AUTOSAR XML (schema 4-2-2)
package /SwComponentType
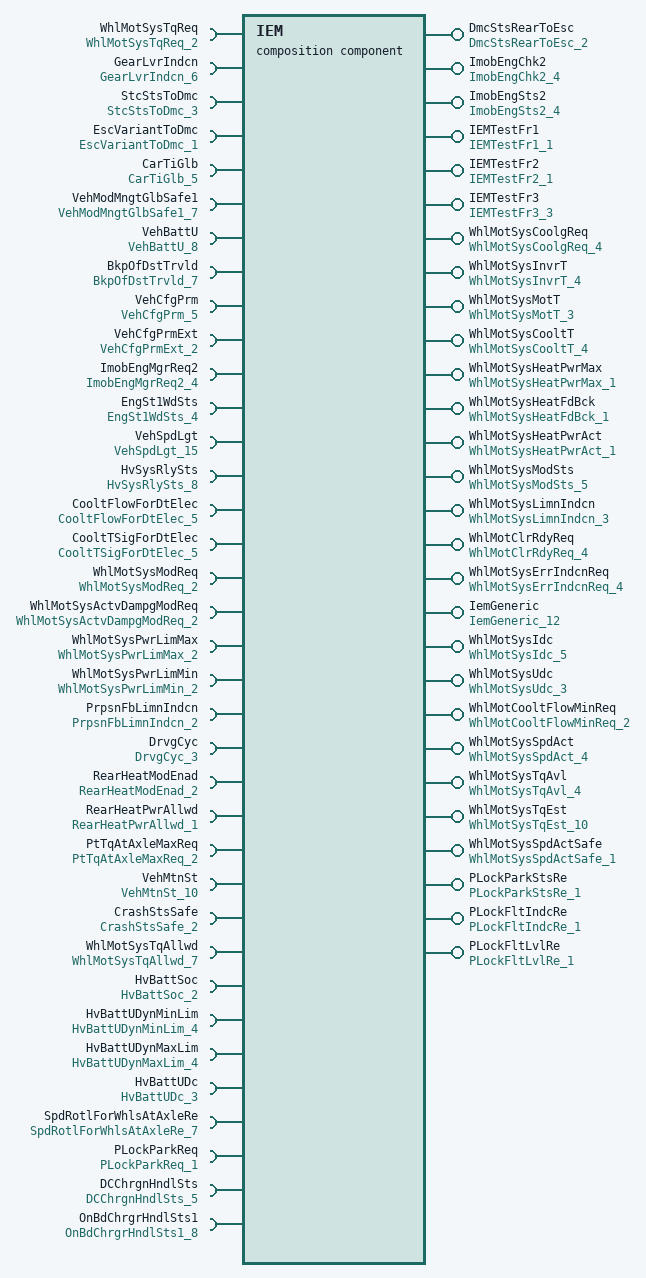
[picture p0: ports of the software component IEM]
  composition sw component type IEM
    28 x provide port:
      DmcStsRearToEsc: nonqueued-sender-com-spec{composite-network-representations=[{leaf-element=DmcStsRearToEsc.DmcSts, network-representation={base-type=DMC_1, compu {0=DMC_Init, 1=DMC_On, 2=DMC_Off, 3=DMC_Fault; unit Unitless}, "DmcSts"}}, {leaf-element=DmcStsRearToEsc.DmcActAppTarTq, network-representation={base-type=Tq35_1, compu {phys=raw for raw -30000..30000; unit NewtonMeter}, "DMCActAppTarTq"}}, {leaf-element=DmcStsRearToEsc.Cntr, network-representation={base-type=UInt4_2, compu {identical; unit Unitless}, "Cntr"}}, {leaf-element=DmcStsRearToEsc.Chks, network-representation={base-type=UInt8_2, compu {identical; unit Unitless}, "Chks"}}, {leaf-element=DmcStsRearToEsc.DmcSWInfo, network-representation={base-type=UInt16_2, compu {identical; unit Unitless}, "DmCSWinformation"}}], data-element=DmcStsRearToEsc, uses-end-to-end-protection=true, init-value=constant-reference=DmcStsRearToEsc_2}, provided-interface=DmcStsRearToEsc_2
      ImobEngChk2: nonqueued-sender-com-spec{composite-network-representations=[{leaf-element=ImobEngChk2.ImobEngChkSts, network-representation={base-type=AvlSts2_2, compu {0=AvlSts2_NotAvl, 1=AvlSts2_Avl; unit Unitless}, "Message from IEM to CEM that challenge is available and 7 bytes of challenge. Message to CEM Challenge available"}}, {leaf-element=ImobEngChk2.ImobEngDataChk0, network-representation={base-type=UInt8_2, compu {identical; unit Unitless}, "Message from IEM to CEM that challenge is available and 7 bytes of challenge. Byte 0"}}, {leaf-element=ImobEngChk2.ImobEngDataChk1, network-representation={base-type=UInt8_2, compu {identical; unit Unitless}, "Message from IEM to CEM that challenge is available and 7 bytes of challenge. Byte 1"}}, {leaf-element=ImobEngChk2.ImobEngDataChk2, network-representation={base-type=UInt8_2, compu {identical; unit Unitless}, "Message from IEM to CEM that challenge is available and 7 bytes of challenge. Byte 2"}}, {leaf-element=ImobEngChk2.ImobEngDataChk3, network-representation={base-type=UInt8_2, compu {identical; unit Unitless}, "Message from IEM to CEM that challenge is available and 7 bytes of challenge. Byte 3"}}, {leaf-element=ImobEngChk2.ImobEngDataChk4, network-representation={base-type=UInt8_2, compu {identical; unit Unitless}, "Message from IEM to CEM that challenge is available and 7 bytes of challenge. Byte 4"}}, {leaf-element=ImobEngChk2.ImobEngDataChk5, network-representation={base-type=UInt8_2, compu {identical; unit Unitless}, "Message from IEM to CEM that challenge is available and 7 bytes of challenge. Byte 5"}}, {leaf-element=ImobEngChk2.ImobEngDataChk6, network-representation={base-type=UInt8_2, compu {identical; unit Unitless}, "Message from IEM to CEM that challenge is available and 7 bytes of challenge. Byte 6"}}], data-element=ImobEngChk2, init-value=constant-reference=ImobEngChk2_4}, provided-interface=ImobEngChk2_4
      ImobEngSts2: nonqueued-sender-com-spec{data-element=ImobEngSts2, network-representation={base-type=ImobSts_2, compu-method=ImobSts_1, "IEM CEM message immo status. Can be undefined, immobilised, motive mobilised or non motive mobilised."}, init-value=constant-reference=ImobEngSts2_4}, provided-interface=ImobEngSts2_4
      IEMTestFr1: nonqueued-sender-com-spec{composite-network-representations=[{leaf-element=IEMTestFr1.Byte0, network-representation={base-type=UInt8_2, compu {identical; unit Unitless}, "DTC1 status"}}, {leaf-element=IEMTestFr1.Byte1, network-representation={base-type=UInt8_2, compu {identical; unit Unitless}, "DTC1 low byte"}}, {leaf-element=IEMTestFr1.Byte2, network-representation={base-type=UInt8_2, compu {identical; unit Unitless}, "DTC1 middle byte"}}, {leaf-element=IEMTestFr1.Byte3, network-representation={base-type=UInt8_2, compu {identical; unit Unitless}, "DTC1 high byte"}}, {leaf-element=IEMTestFr1.Byte4, network-representation={base-type=UInt8_2, compu {identical; unit Unitless}, "DTC2 status"}}, {leaf-element=IEMTestFr1.Byte5, network-representation={base-type=UInt8_2, compu {identical; unit Unitless}, "DTC2 low byte"}}, {leaf-element=IEMTestFr1.Byte6, network-representation={base-type=UInt8_2, compu {identical; unit Unitless}, "DTC2 middle byte"}}, {leaf-element=IEMTestFr1.Byte7, network-representation={base-type=UInt8_2, compu {identical; unit Unitless}, "DTC2 high byte"}}], data-element=IEMTestFr1, init-value=constant-reference=IEMTestFr1_1}, provided-interface=IEMTestFr1_1
      IEMTestFr2: nonqueued-sender-com-spec{composite-network-representations=[{leaf-element=IEMTestFr2.Byte0, network-representation={base-type=UInt8_2, compu {identical; unit Unitless}, "DTC1 status"}}, {leaf-element=IEMTestFr2.Byte1, network-representation={base-type=UInt8_2, compu {identical; unit Unitless}, "DTC1 low byte"}}, {leaf-element=IEMTestFr2.Byte2, network-representation={base-type=UInt8_2, compu {identical; unit Unitless}, "DTC1 middle byte"}}, {leaf-element=IEMTestFr2.Byte3, network-representation={base-type=UInt8_2, compu {identical; unit Unitless}, "DTC1 high byte"}}, {leaf-element=IEMTestFr2.Byte4, network-representation={base-type=UInt8_2, compu {identical; unit Unitless}, "DTC2 status"}}, {leaf-element=IEMTestFr2.Byte5, network-representation={base-type=UInt8_2, compu {identical; unit Unitless}, "DTC2 low byte"}}, {leaf-element=IEMTestFr2.Byte6, network-representation={base-type=UInt8_2, compu {identical; unit Unitless}, "DTC2 middle byte"}}, {leaf-element=IEMTestFr2.Byte7, network-representation={base-type=UInt8_2, compu {identical; unit Unitless}, "DTC2 high byte"}}], data-element=IEMTestFr2, init-value=constant-reference=IEMTestFr2_1}, provided-interface=IEMTestFr2_1
      IEMTestFr3: nonqueued-sender-com-spec{composite-network-representations=[{leaf-element=IEMTestFr3.Byte0, network-representation={base-type=UInt8_2, compu {identical; unit Unitless}, "Info0"}}, {leaf-element=IEMTestFr3.Byte1, network-representation={base-type=UInt8_2, compu {identical; unit Unitless}, "Info1"}}, {leaf-element=IEMTestFr3.Byte2, network-representation={base-type=UInt8_2, compu {identical; unit Unitless}, "Info2"}}, {leaf-element=IEMTestFr3.Byte3, network-representation={base-type=UInt8_2, compu {identical; unit Unitless}, "Info3"}}, {leaf-element=IEMTestFr3.Byte4, network-representation={base-type=UInt8_2, compu {identical; unit Unitless}, "Info4"}}, {leaf-element=IEMTestFr3.Byte5, network-representation={base-type=UInt8_2, compu {identical; unit Unitless}, "Info5"}}, {leaf-element=IEMTestFr3.Byte6, network-representation={base-type=UInt8_2, compu {identical; unit Unitless}, "Info6"}}, {leaf-element=IEMTestFr3.Byte7, network-representation={base-type=UInt8_2, compu {identical; unit Unitless}, "Info7"}}], data-element=IEMTestFr3, init-value=constant-reference=IEMTestFr3_3}, provided-interface=IEMTestFr3_3
      WhlMotSysCoolgReq: nonqueued-sender-com-spec{data-element=WhlMotSysCoolgReq, network-representation={base-type=HvCoolg1_2, compu-method=HvCoolg1_1, "Signal to request increased cooling to Erad and IEM.Request is in 3 steps of increased cooling."}, init-value=constant-reference=WhlMotSysCoolgReq_4}, provided-interface=WhlMotSysCoolgReq_4
      WhlMotSysInvrT: nonqueued-sender-com-spec{data-element=WhlMotSysInvrT, network-representation={base-type=T3_2, compu {phys=raw-50 for raw 0..250; unit degC}, "The inverter temperature measured in the IEM."}, init-value=constant-reference=WhlMotSysInvrT_4}, provided-interface=WhlMotSysInvrT_4
      WhlMotSysMotT: nonqueued-sender-com-spec{data-element=WhlMotSysMotT, network-representation={base-type=T3_2, compu {phys=raw-50 for raw 0..250; unit degC}, "The temperature of motor"}, init-value=constant-reference=WhlMotSysMotT_3}, provided-interface=WhlMotSysMotT_3
      WhlMotSysCooltT: nonqueued-sender-com-spec{data-element=WhlMotSysCooltT, network-representation={base-type=HvT1_3, compu {phys=raw-40 for raw 0..255; unit degC}, "Measured coolant temperature in rear axle inverter in degC"}, init-value=constant-reference=WhlMotSysCooltT_4}, provided-interface=WhlMotSysCooltT_4
      WhlMotSysHeatPwrMax: nonqueued-sender-com-spec{data-element=WhlMotSysHeatPwrMax, network-representation={base-type=IsgHeatPwr_1, compu {phys=raw*50 for raw 0..255; unit W}, "The electrical power required by the current maximum heating power of the rear motor"}, init-value=constant-reference=WhlMotSysHeatPwrMax_1}, provided-interface=WhlMotSysHeatPwrMax_1
      WhlMotSysHeatFdBck: nonqueued-sender-com-spec{data-element=WhlMotSysHeatFdBck, network-representation={base-type=WhlMotSysHeatFdBck_1, compu-method=WhlMotSysHeatFdBck_1, "The feedback of the rear motor to responds to the heating enabling signal of ECM"}, init-value=constant-reference=WhlMotSysHeatFdBck_1}, provided-interface=WhlMotSysHeatFdBck_1
      WhlMotSysHeatPwrAct: nonqueued-sender-com-spec{data-element=WhlMotSysHeatPwrAct, network-representation={base-type=IsgHeatPwr_1, compu {phys=raw*50 for raw 0..255; unit W}, "The actual electrical energy consumption for active heating of rear motor"}, init-value=constant-reference=WhlMotSysHeatPwrAct_1}, provided-interface=WhlMotSysHeatPwrAct_1
      WhlMotSysModSts: nonqueued-sender-com-spec{data-element=WhlMotSysModSts, network-representation={base-type=WhlMotSysModStsTyp2_2, compu-method=WhlMotSysModStsTyp2_2, "Reflects the current operating mode of the IEM."}, init-value=constant-reference=WhlMotSysModSts_5}, provided-interface=WhlMotSysModSts_5
      WhlMotSysLimnIndcn: nonqueued-sender-com-spec{data-element=WhlMotSysLimnIndcn, network-representation={base-type=UInt16_2, compu {identical; unit Unitless}, "The limitation indication of derating conditions"}, init-value=constant-reference=WhlMotSysLimnIndcn_3}, provided-interface=WhlMotSysLimnIndcn_3
      WhlMotClrRdyReq: nonqueued-sender-com-spec{data-element=WhlMotClrRdyReq, network-representation={base-type=OnOff1_2, compu {0=OnOff1_Off, 1=OnOff1_On; unit Unitless}, "WhlMotClrRdyReq"}, init-value=constant-reference=WhlMotClrRdyReq_4}, provided-interface=WhlMotClrRdyReq_4
      WhlMotSysErrIndcnReq: nonqueued-sender-com-spec{data-element=WhlMotSysErrIndcnReq, network-representation={base-type=OnOff1_2, compu {0=OnOff1_Off, 1=OnOff1_On; unit Unitless}, "WhlMotSysErrIndcnReq"}, init-value=constant-reference=WhlMotSysErrIndcnReq_4}, provided-interface=WhlMotSysErrIndcnReq_4
      IemGeneric: nonqueued-sender-com-spec{composite-network-representations=[{leaf-element=IemGeneric.EMQnty, network-representation={base-type=UInt4_2, compu {identical; unit Unitless}, "Quantity of electric motor"}}, {leaf-element=IemGeneric.EMSeqNr, network-representation={base-type=UInt4_2, compu {identical; unit Unitless}, "Sequence number of electric motor"}}, {leaf-element=IemGeneric.DTCSts, network-representation={base-type=UInt8_2, compu {identical; unit Unitless}, "DTC Status"}}, {leaf-element=IemGeneric.DTCLow, network-representation={base-type=UInt8_2, compu {identical; unit Unitless}, "DTC low byte for non OBD"}}, {leaf-element=IemGeneric.DTCMid, network-representation={base-type=UInt8_2, compu {identical; unit Unitless}, "DTC middle byte for non OBD DTC low byte for OBD"}}, {leaf-element=IemGeneric.DTCHig, network-representation={base-type=UInt8_2, compu {identical; unit Unitless}, "DTC high byte for non OBD or OBD"}}, {leaf-element=IemGeneric.TypeInfo, network-representation={base-type=UInt4_2, compu {identical; unit Unitless}, "Indicate different EDS suppliers. OEM defines this value. 0=not defined 1=PMA1 VseA, with ratio=10.134 2=PMA1 Nidec,with ratio=10.294 3=PMA1 VREMT,with ratio=11.56 4=SPAL Scheaffler,with ratio=9.071 5=SPA Simens, with ratio=10.008 6=PMA2 VREMT,with ratio=11.209 7=EPA ZF,with radio=9.187 8=EPA Polestar,with 2-gear ratio=7.155 and 13.645 9=PMA2 UAES,with ratio=11.067"}}, {leaf-element=IemGeneric.MotTAlrmSt, network-representation={base-type=AlrmSt_2, compu {0=AlrmSt_Disarmd, 1=AlrmSt_Armd, 2=AlrmSt_Actv; unit Unitless}, "Motor temperature alarm status"}}, {leaf-element=IemGeneric.InvrtTAlrmSt, network-representation={base-type=AlrmSt_2, compu {0=AlrmSt_Disarmd, 1=AlrmSt_Armd, 2=AlrmSt_Actv; unit Unitless}, "Inverter temperature alarm status"}}, {leaf-element=IemGeneric.FltAlrmSt, network-representation={base-type=AlrmSt_2, compu {0=AlrmSt_Disarmd, 1=AlrmSt_Armd, 2=AlrmSt_Actv; unit Unitless}, "Fault alarm status"}}, {leaf-element=IemGeneric.SpdAlrmSt, network-representation={base-type=AlrmSt_2, compu {0=AlrmSt_Disarmd, 1=AlrmSt_Armd, 2=AlrmSt_Actv; unit Unitless}, "Over speed alarm status"}}, {leaf-element=IemGeneric.IacAlrmSt, network-representation={base-type=AlrmSt_2, compu {0=AlrmSt_Disarmd, 1=AlrmSt_Armd, 2=AlrmSt_Actv; unit Unitless}, "3 Phase current alarm status"}}, {leaf-element=IemGeneric.UDcAlrmSt, network-representation={base-type=AlrmSt_2, compu {0=AlrmSt_Disarmd, 1=AlrmSt_Armd, 2=AlrmSt_Actv; unit Unitless}, "High voltage alarm status"}}, {leaf-element=IemGeneric.RslAlrmSt, network-representation={base-type=AlrmSt_2, compu {0=AlrmSt_Disarmd, 1=AlrmSt_Armd, 2=AlrmSt_Actv; unit Unitless}, "Resolver fault alarm status"}}, {leaf-element=IemGeneric.ADAlrmSt, network-representation={base-type=AlrmSt_2, compu {0=AlrmSt_Disarmd, 1=AlrmSt_Armd, 2=AlrmSt_Actv; unit Unitless}, "Active Discharge fault alarm status"}}, {leaf-element=IemGeneric.ModStatusRms, network-representation={base-type=ModStatusRms_2, compu-method=ModStatusRms_2, "Motor status for RMS monitor"}}], data-element=IemGeneric, init-value=constant-reference=IemGeneric_12}, provided-interface=IemGeneric_12
      WhlMotSysIdc: nonqueued-sender-com-spec{data-element=WhlMotSysIdc, network-representation={base-type=Ampr1_1, compu {phys=raw*0.1-818.8 for raw 0..16380; unit A}, "DC current measured in the IEM."}, init-value=constant-reference=WhlMotSysIdc_5}, provided-interface=WhlMotSysIdc_5
      WhlMotSysUdc: nonqueued-sender-com-spec{data-element=WhlMotSysUdc, network-representation={base-type=HvU1_2, compu {phys=raw*0.25 for raw 0..2044; unit Volt}, "The DC voltage of rear motor"}, init-value=constant-reference=WhlMotSysUdc_3}, provided-interface=WhlMotSysUdc_3
      WhlMotCooltFlowMinReq: nonqueued-sender-com-spec{data-element=WhlMotCooltFlowMinReq, network-representation={base-type=CooltFlowForDtElec1_2, compu {phys=raw*0.01 for raw 0..1023; unit L / min}, "Minimum coolant flow required by rear wheel motor"}, init-value=constant-reference=WhlMotCooltFlowMinReq_2}, provided-interface=WhlMotCooltFlowMinReq_2
      WhlMotSysSpdAct: nonqueued-sender-com-spec{data-element=WhlMotSysSpdAct, network-representation={base-type=IsgSpdWSgnTyp_2, compu {phys=raw for raw -16384..16383; unit rpm}, "The actual rotational speed of rear motor"}, init-value=constant-reference=WhlMotSysSpdAct_4}, provided-interface=WhlMotSysSpdAct_4
      WhlMotSysTqAvl: nonqueued-sender-com-spec{composite-network-representations=[{leaf-element=WhlMotSysTqAvl.TqAvlMax, network-representation={base-type=HvTq1_2, compu {phys=raw*4-8188 for raw 0..4095; unit NewtonMeter}, "Max available torque"}}, {leaf-element=WhlMotSysTqAvl.TqAvlMin, network-representation={base-type=HvTq1_2, compu {phys=raw*4-8188 for raw 0..4095; unit NewtonMeter}, "Min available torque"}}], data-element=WhlMotSysTqAvl, init-value=constant-reference=WhlMotSysTqAvl_4}, provided-interface=WhlMotSysTqAvl_4
      WhlMotSysTqEst: nonqueued-sender-com-spec{composite-network-representations=[{leaf-element=WhlMotSysTqEst.Cntr, network-representation={base-type=UInt4_2, compu {identical; unit Unitless}, "Counter of estimation torque"}}, {leaf-element=WhlMotSysTqEst.Chks, network-representation={base-type=UInt8_2, compu {identical; unit Unitless}, "Checksum of estimation torque"}}, {leaf-element=WhlMotSysTqEst.QualityFactor, network-representation={base-type=QualityFactor_2, compu-method=QualityFactor_1, "Quality factor of estimation torque"}}, {leaf-element=WhlMotSysTqEst.IsgTqAct, network-representation={base-type=Tq34_1, compu {phys=raw-8188 for raw 0..16380; unit NewtonMeter}, "Estimation torque of Rear Axle Control"}}], data-element=WhlMotSysTqEst, uses-end-to-end-protection=true, init-value=constant-reference=WhlMotSysTqEst_10}, provided-interface=WhlMotSysTqEst_10
      WhlMotSysSpdActSafe: nonqueued-sender-com-spec{composite-network-representations=[{leaf-element=WhlMotSysSpdActSafe.IsgSpdWSgnTyp, network-representation={base-type=IsgSpdWSgnTyp_2, compu {phys=raw for raw -16384..16383; unit rpm}, "Safe EM motor shaft speed."}}, {leaf-element=WhlMotSysSpdActSafe.Chks, network-representation={base-type=UInt8_2, compu {identical; unit Unitless}, "checksum"}}, {leaf-element=WhlMotSysSpdActSafe.Cntr, network-representation={base-type=UInt4_2, compu {identical; unit Unitless}, "counter"}}, {leaf-element=WhlMotSysSpdActSafe.Qf, network-representation={base-type=GenQf1_2, compu-method=GenQf1_1, "quality factor"}}], data-element=WhlMotSysSpdActSafe, uses-end-to-end-protection=true, init-value=constant-reference=WhlMotSysSpdActSafe_1}, provided-interface=WhlMotSysSpdActSafe_1
      PLockParkStsRe: nonqueued-sender-com-spec{data-element=PLockParkStsRe, network-representation={base-type=ParkSts_1, compu-method=ParkSts_1, "P-lock status (IEM)"}, init-value=constant-reference=PLockParkStsRe_1}, provided-interface=PLockParkStsRe_1
      PLockFltIndcRe: nonqueued-sender-com-spec{data-element=PLockFltIndcRe, network-representation={base-type=FltIndcn_1, compu-method=FltIndcn_1, "Fault indication signal for P-lock, for rear electric drive"}, init-value=constant-reference=PLockFltIndcRe_1}, provided-interface=PLockFltIndcRe_1
      PLockFltLvlRe: nonqueued-sender-com-spec{data-element=PLockFltLvlRe, network-representation={base-type=FltLvl_1, compu {0=FltLvl_NoFlt, 1=FltLvl_FltLvl1, 2=FltLvl_FltLvl2; unit Unitless}, "P-lock fault level, for rear electric drive."}, init-value=constant-reference=PLockFltLvlRe_1}, provided-interface=PLockFltLvlRe_1
    36 x require port:
      WhlMotSysTqReq: nonqueued-receiver-com-spec{data-element=WhlMotSysTqReq, network-representation={base-type=HvTq1_2, compu {phys=raw*4-8188 for raw 0..4095; unit NewtonMeter}, "Requested electric motor torque referred to the wheel axle. The torque is positive in the forward rotation direction."}, alive-timeout=0.5, init-value=constant-reference=WhlMotSysTqReq_2}, required-interface=WhlMotSysTqReq_2
      GearLvrIndcn: nonqueued-receiver-com-spec{data-element=GearLvrIndcn, network-representation={base-type=GearLvrIndcn2_2, compu-method=GearLvrIndcn2_1, "Gear lever indication (drivetrain position) to the driver. If drivetrain position is not possible to decide signal is set to undefined. Valid for automatic vehicles."}, init-value=constant-reference=GearLvrIndcn_6}, required-interface=GearLvrIndcn_6
      StcStsToDmc: nonqueued-receiver-com-spec{composite-network-representations=[{leaf-element=StcStsToDmc.StcStsToDmcFrnt, network-representation={base-type=ModeDMC_1, compu {0=ModeDMC_Off, 1=ModeDMC_Rpm, 2=ModeDMC_Trq; unit Unitless}, "StcSts to Dmc frint"}}, {leaf-element=StcStsToDmc.StcStsToDmcRear, network-representation={base-type=ModeDMC_1, compu {0=ModeDMC_Off, 1=ModeDMC_Rpm, 2=ModeDMC_Trq; unit Unitless}, "StcSts to DMC Rear"}}, {leaf-element=StcStsToDmc.EngRotTarSpdDMCFrnt, network-representation={base-type=UInt16_2, compu {identical; unit Unitless}, "EngRoTarSpdDMC frint"}}, {leaf-element=StcStsToDmc.EngRotTarSpdDMCRear, network-representation={base-type=UInt16_2, compu {identical; unit Unitless}, "EngRoTarSpdDMC rear"}}, {leaf-element=StcStsToDmc.Chks, network-representation={base-type=UInt8_2, compu {identical; unit Unitless}, "Chks"}}, {leaf-element=StcStsToDmc.Cntr, network-representation={base-type=UInt4_2, compu {identical; unit Unitless}, "Cntr"}}], data-element=StcStsToDmc, uses-end-to-end-protection=true, init-value=constant-reference=StcStsToDmc_3}, required-interface=StcStsToDmc_3
      EscVariantToDmc: nonqueued-receiver-com-spec{composite-network-representations=[{leaf-element=EscVariantToDmc.EscVariantToDmc, network-representation={base-type=UInt8_2, compu {identical; unit Unitless}, "Esc Variant"}}, {leaf-element=EscVariantToDmc.Chks, network-representation={base-type=UInt8_2, compu {identical; unit Unitless}, "Chks"}}, {leaf-element=EscVariantToDmc.Cntr, network-representation={base-type=UInt4_2, compu {identical; unit Unitless}, "Cntr"}}], data-element=EscVariantToDmc, uses-end-to-end-protection=true, init-value=constant-reference=EscVariantToDmc_1}, required-interface=EscVariantToDmc_1
      CarTiGlb: nonqueued-receiver-com-spec{data-element=CarTiGlb, network-representation={base-type=CarTiGlb_2, compu {phys=raw*0.1 for raw 0..4294967295; unit s}, "Presents a tiime value that shall be used by all ECUs to time-stamp diagnsotic trouble codes (DTC) according to the requirements for Global DTC snapshot data."}, init-value=constant-reference=CarTiGlb_5}, required-interface=CarTiGlb_5
      VehModMngtGlbSafe1: nonqueued-receiver-com-spec{composite-network-representations=[{leaf-element=VehModMngtGlbSafe1.UsgModSts, network-representation={base-type=UsgModSts1_2, compu-method=UsgModSts1_1, "UsageMode Status"}}, {leaf-element=VehModMngtGlbSafe1.CarModSts1, network-representation={base-type=CarModSts1_2, compu-method=CarModSts1_1, "CarMode Status"}}, {leaf-element=VehModMngtGlbSafe1.CarModSubtypWdCarModSubtyp, network-representation={base-type=Nr5_2, compu {identical; unit Unitless}, "CarMode substate status"}}, {leaf-element=VehModMngtGlbSafe1.EgyLvlElecMai, network-representation={base-type=UInt4_2, compu {identical; unit Unitless}, "Main energy level in the vehicle."}}, {leaf-element=VehModMngtGlbSafe1.EgyLvlElecSubtyp, network-representation={base-type=UInt4_2, compu {identical; unit Unitless}, "Substate of the energy level in the vehicle."}}, {leaf-element=VehModMngtGlbSafe1.PwrLvlElecMai, network-representation={base-type=UInt4_2, compu {identical; unit Unitless}, "Main Power level in the vehicle."}}, {leaf-element=VehModMngtGlbSafe1.PwrLvlElecSubtyp, network-representation={base-type=UInt4_2, compu {identical; unit Unitless}, "Substate of the power level in the vehicle."}}, {leaf-element=VehModMngtGlbSafe1.FltEgyCnsWdSts, network-representation={base-type=FltEgyCns1_2, compu {0=FltEgyCns1_NoFlt, 1=FltEgyCns1_Flt; unit Unitless}, "High quiescent current detected by CEM via BMS."}}, {leaf-element=VehModMngtGlbSafe1.Chks, network-representation={base-type=UInt8_2, compu {identical; unit Unitless}, "Checksum"}}, {leaf-element=VehModMngtGlbSafe1.Cntr, network-representation={base-type=UInt4_2, compu {identical; unit Unitless}, "Counter"}}], data-element=VehModMngtGlbSafe1, init-value=constant-reference=VehModMngtGlbSafe1_7}, required-interface=VehModMngtGlbSafe1_7
      VehBattU: nonqueued-receiver-com-spec{composite-network-representations=[{leaf-element=VehBattU.SysU, network-representation={base-type=U1_2, compu {phys=raw*0.1 for raw 0..250; unit Volt}, "Vehicle System Voltage At 12V side"}}, {leaf-element=VehBattU.SysUQf, network-representation={base-type=GenQf1_2, compu-method=GenQf1_1, "Present vehicle voltage measured by CEM with QF"}}], data-element=VehBattU, init-value=constant-reference=VehBattU_8}, required-interface=VehBattU_8
      BkpOfDstTrvld: nonqueued-receiver-com-spec{data-element=BkpOfDstTrvld, network-representation={base-type=Len31_2, compu {phys=raw for raw 0..2000000; unit km}, "total traveled distance."}, init-value=constant-reference=BkpOfDstTrvld_7}, required-interface=BkpOfDstTrvld_7
      VehCfgPrm: nonqueued-receiver-com-spec{composite-network-representations=[{leaf-element=VehCfgPrm.BlkIDBytePosn1, network-representation={base-type=Nr2_3, compu {phys=raw for raw 0..255; unit Unitless}, "signal block counter."}}, {leaf-element=VehCfgPrm.CCPBytePosn2, network-representation={base-type=Nr2_3, compu {phys=raw for raw 0..255; unit Unitless}, "(BlockID-1)*7 + 1."}}, {leaf-element=VehCfgPrm.CCPBytePosn3, network-representation={base-type=Nr2_3, compu {phys=raw for raw 0..255; unit Unitless}, "(BlockID-1)*7 + 2."}}, {leaf-element=VehCfgPrm.CCPBytePosn4, network-representation={base-type=Nr2_3, compu {phys=raw for raw 0..255; unit Unitless}, "(BlockID-1)*7 + 3."}}, {leaf-element=VehCfgPrm.CCPBytePosn5, network-representation={base-type=Nr2_3, compu {phys=raw for raw 0..255; unit Unitless}, "(BlockID-1)*7 + 4."}}, {leaf-element=VehCfgPrm.CCPBytePosn6, network-representation={base-type=Nr2_3, compu {phys=raw for raw 0..255; unit Unitless}, "(BlockID-1)*7 + 5."}}, {leaf-element=VehCfgPrm.CCPBytePosn7, network-representation={base-type=Nr2_3, compu {phys=raw for raw 0..255; unit Unitless}, "(BlockID-1)*7 + 6."}}, {leaf-element=VehCfgPrm.CCPBytePosn8, network-representation={base-type=Nr2_3, compu {phys=raw for raw 0..255; unit Unitless}, "(BlockID-1)*7 + 7."}}], data-element=VehCfgPrm, init-value=constant-reference=VehCfgPrm_5}, required-interface=VehCfgPrm_5
      VehCfgPrmExt: nonqueued-receiver-com-spec{composite-network-representations=[{leaf-element=VehCfgPrmExt.BlkIDBytePosn1, network-representation={base-type=Nr2_3, compu {phys=raw for raw 0..255; unit Unitless}, "CarConfigExtended BlockID"}}, {leaf-element=VehCfgPrmExt.CCPBytePosn2, network-representation={base-type=Nr2_3, compu {phys=raw for raw 0..255; unit Unitless}, "CarConfigExtended BytePos2"}}, {leaf-element=VehCfgPrmExt.CCPBytePosn3, network-representation={base-type=Nr2_3, compu {phys=raw for raw 0..255; unit Unitless}, "CarConfigExtended BytePos3"}}, {leaf-element=VehCfgPrmExt.CCPBytePosn4, network-representation={base-type=Nr2_3, compu {phys=raw for raw 0..255; unit Unitless}, "CarConfigExtended BytePos4"}}, {leaf-element=VehCfgPrmExt.CCPBytePosn5, network-representation={base-type=Nr2_3, compu {phys=raw for raw 0..255; unit Unitless}, "CarConfigExtended BytePos5"}}, {leaf-element=VehCfgPrmExt.CCPBytePosn6, network-representation={base-type=Nr2_3, compu {phys=raw for raw 0..255; unit Unitless}, "CarConfigExtended BytePos6"}}, {leaf-element=VehCfgPrmExt.CCPBytePosn7, network-representation={base-type=Nr2_3, compu {phys=raw for raw 0..255; unit Unitless}, "CarConfigExtended BytePos7"}}, {leaf-element=VehCfgPrmExt.CCPBytePosn8, network-representation={base-type=Nr2_3, compu {phys=raw for raw 0..255; unit Unitless}, "CarConfigExtended BytePos8"}}], data-element=VehCfgPrmExt, init-value=constant-reference=VehCfgPrmExt_2}, required-interface=VehCfgPrmExt_2
      ImobEngMgrReq2: nonqueued-receiver-com-spec{composite-network-representations=[{leaf-element=ImobEngMgrReq2.ImobEngMgrCmdTar1, network-representation={base-type=ImobEngMgrReqCmd_2, compu-method=ImobEngMgrReqCmd_1, "Command from CEM to IEM with desired immo status and 7 bytes of response Command from CEM"}}, {leaf-element=ImobEngMgrReq2.ImobEngDataMgrReq0, network-representation={base-type=UInt8_2, compu {identical; unit Unitless}, "Command from CEM to IEM with desired immo status and 7 bytes of response Byte 0"}}, {leaf-element=ImobEngMgrReq2.ImobEngDataMgrReq1, network-representation={base-type=UInt8_2, compu {identical; unit Unitless}, "Command from CEM to IEM with desired immo status and 7 bytes of response Byte 1"}}, {leaf-element=ImobEngMgrReq2.ImobEngDataMgrReq2, network-representation={base-type=UInt8_2, compu {identical; unit Unitless}, "Command from CEM to IEM with desired immo status and 7 bytes of response Byte 2"}}, {leaf-element=ImobEngMgrReq2.ImobEngDataMgrReq3, network-representation={base-type=UInt8_2, compu {identical; unit Unitless}, "Command from CEM to IEM with desired immo status and 7 bytes of response Byte 3"}}, {leaf-element=ImobEngMgrReq2.ImobEngDataMgrReq4, network-representation={base-type=UInt8_2, compu {identical; unit Unitless}, "Command from CEM to IEM with desired immo status and 7 bytes of response Byte 4"}}, {leaf-element=ImobEngMgrReq2.ImobEngDataMgrReq5, network-representation={base-type=UInt8_2, compu {identical; unit Unitless}, "Command from CEM to IEM with desired immo status and 7 bytes of response Byte 5"}}, {leaf-element=ImobEngMgrReq2.ImobEngDataMgrReq6, network-representation={base-type=UInt8_2, compu {identical; unit Unitless}, "Command from CEM to IEM with desired immo status and 7 bytes of response Byte 6"}}], data-element=ImobEngMgrReq2, init-value=constant-reference=ImobEngMgrReq2_4}, required-interface=ImobEngMgrReq2_4
      EngSt1WdSts: nonqueued-receiver-com-spec{composite-network-representations=[{leaf-element=EngSt1WdSts.EngSt1WdSts, network-representation={base-type=EngSt1_2, compu-method=EngSt1_1, "Signaling the state of the powerpack"}}, {leaf-element=EngSt1WdSts.Chks, network-representation={base-type=UInt8_2, compu {identical; unit Unitless}, "checksum"}}, {leaf-element=EngSt1WdSts.Cntr, network-representation={base-type=UInt4_2, compu {identical; unit Unitless}, "counter"}}], data-element=EngSt1WdSts, init-value=constant-reference=EngSt1WdSts_4}, required-interface=EngSt1WdSts_4
      VehSpdLgt: nonqueued-receiver-com-spec{composite-network-representations=[{leaf-element=VehSpdLgt.VehSpdLgtA, network-representation={base-type=Spd1_2, compu {phys=raw*0.00391 for raw 0..31970; unit m/s}, "Vehicle speed longitudinal based on wheel speed sensors and longitudinal acceleration."}}, {leaf-element=VehSpdLgt.VehSpdLgtQf, network-representation={base-type=GenQf1_2, compu-method=GenQf1_1, "Quality factor for vehicle speed as measured by wheel speed sensors and longitudinal acceleration."}}, {leaf-element=VehSpdLgt.VehSpdLgtCntr, network-representation={base-type=UInt4_2, compu {identical; unit Unitless}, "Counter"}}, {leaf-element=VehSpdLgt.VehSpdLgtChks, network-representation={base-type=UInt8_2, compu {identical; unit Unitless}, "Checksum"}}], data-element=VehSpdLgt, uses-end-to-end-protection=true, init-value=constant-reference=VehSpdLgt_15}, required-interface=VehSpdLgt_15
      HvSysRlySts: nonqueued-receiver-com-spec{composite-network-representations=[{leaf-element=HvSysRlySts.HvSysRlySts, network-representation={base-type=HvActvnSts_2, compu-method=HvActvnSts_1, "Actual state of the main contactors."}}, {leaf-element=HvSysRlySts.Cntr, network-representation={base-type=UInt4_2, compu {identical; unit Unitless}, "Counter for E2E"}}, {leaf-element=HvSysRlySts.Chks, network-representation={base-type=UInt8_2, compu {identical; unit Unitless}, "Checksum for E2E"}}], data-element=HvSysRlySts, uses-end-to-end-protection=true, alive-timeout=0.35, init-value=constant-reference=HvSysRlySts_8}, required-interface=HvSysRlySts_8
      CooltFlowForDtElec: nonqueued-receiver-com-spec{data-element=CooltFlowForDtElec, network-representation={base-type=CooltFlow2_2, compu {phys=raw*0.1 for raw 0..511; unit L / min}, "Predicted coolant low for Electric Drivetrain (ED) coolant circuit."}, init-value=constant-reference=CooltFlowForDtElec_5}, required-interface=CooltFlowForDtElec_5
      CooltTSigForDtElec: nonqueued-receiver-com-spec{data-element=CooltTSigForDtElec, network-representation={base-type=CooltTHiResl_2, compu {phys=raw*0.1-40 for raw 0..1800; unit degC}, "Coolant temperature measured by sensors installed in emotor cooling citcuit."}, init-value=constant-reference=CooltTSigForDtElec_5}, required-interface=CooltTSigForDtElec_5
      WhlMotSysModReq: nonqueued-receiver-com-spec{data-element=WhlMotSysModReq, network-representation={base-type=WhlMotSysModStsTyp1_2, compu-method=WhlMotSysModStsTyp1_1, "Mode request for motor drive system connected to wheel shaft."}, alive-timeout=0.5, init-value=constant-reference=WhlMotSysModReq_2}, required-interface=WhlMotSysModReq_2
      WhlMotSysActvDampgModReq: nonqueued-receiver-com-spec{data-element=WhlMotSysActvDampgModReq, network-representation={base-type=WhlMotSysActvDampgModCodSts_2, compu-method=WhlMotSysActvDampgModCodSts_1, "ERAD active damping mod request."}, init-value=constant-reference=WhlMotSysActvDampgModReq_2}, required-interface=WhlMotSysActvDampgModReq_2
      WhlMotSysPwrLimMax: nonqueued-receiver-com-spec{data-element=WhlMotSysPwrLimMax, network-representation={base-type=PrpsnPwrLimMax_2, compu {phys=raw*0.5 for raw 0..1022; unit kW}, "Maximum electric motor powerlimit on DC side. Positive power means power flowing into inverter."}, init-value=constant-reference=WhlMotSysPwrLimMax_2}, required-interface=WhlMotSysPwrLimMax_2
      WhlMotSysPwrLimMin: nonqueued-receiver-com-spec{data-element=WhlMotSysPwrLimMin, network-representation={base-type=PrpsnPwrLimMin_2, compu {phys=raw*0.5-511 for raw 0..1022; unit kW}, "Minimum electric motor powerlimit on DC side. Positive power means power flowing into inverter."}, init-value=constant-reference=WhlMotSysPwrLimMin_2}, required-interface=WhlMotSysPwrLimMin_2
      PrpsnFbLimnIndcn: nonqueued-receiver-com-spec{data-element=PrpsnFbLimnIndcn, network-representation={base-type=UInt4_2, compu {identical; unit Unitless}, "Feedback signal that the present limitation has lead to a recofiguraton that has affected the driver."}, init-value=constant-reference=PrpsnFbLimnIndcn_2}, required-interface=PrpsnFbLimnIndcn_2
      DrvgCyc: nonqueued-receiver-com-spec{data-element=DrvgCyc, network-representation={base-type=OnOff1_2, compu {0=OnOff1_Off, 1=OnOff1_On; unit Unitless}, "Transition from 0 to 1 indicates a start of a new Driving Cycle."}, init-value=constant-reference=DrvgCyc_3}, required-interface=DrvgCyc_3
      RearHeatModEnad: nonqueued-receiver-com-spec{data-element=RearHeatModEnad, network-representation={base-type=FrntHeatModEnad_1, compu-method=FrntHeatModEnad_1, "Active heating enabling signal for rear motor"}, init-value=constant-reference=RearHeatModEnad_2}, required-interface=RearHeatModEnad_2
      RearHeatPwrAllwd: nonqueued-receiver-com-spec{data-element=RearHeatPwrAllwd, network-representation={base-type=IsgHeatPwr_1, compu {phys=raw*50 for raw 0..255; unit W}, "The allowed electrial energy for active heating of the rear motor"}, init-value=constant-reference=RearHeatPwrAllwd_1}, required-interface=RearHeatPwrAllwd_1
      PtTqAtAxleMaxReq: nonqueued-receiver-com-spec{composite-network-representations=[{leaf-element=PtTqAtAxleMaxReq.PtTqAtAxleFrntReq, network-representation={base-type=Tq2_2, compu {phys=raw for raw -20000..20000; unit NewtonMeter}, "Maximum allowed powertrain applied torque on the front axle."}}, {leaf-element=PtTqAtAxleMaxReq.PtTqAtAxleReReq, network-representation={base-type=Tq2_2, compu {phys=raw for raw -20000..20000; unit NewtonMeter}, "Maximum allowed powertrain applied torque on the rear axle."}}, {leaf-element=PtTqAtAxleMaxReq.Chks, network-representation={base-type=UInt8_2, compu {identical; unit Unitless}, "checksum"}}, {leaf-element=PtTqAtAxleMaxReq.Cntr, network-representation={base-type=UInt4_2, compu {identical; unit Unitless}, "counter"}}], data-element=PtTqAtAxleMaxReq, alive-timeout=0.5, init-value=constant-reference=PtTqAtAxleMaxReq_2}, required-interface=PtTqAtAxleMaxReq_2
      VehMtnSt: nonqueued-receiver-com-spec{composite-network-representations=[{leaf-element=VehMtnSt.VehMtnSt, network-representation={base-type=VehMtnSt2_2, compu-method=VehMtnSt2_1, "Vehicle motion state information based on wheel speed sensors. Provides information about vehicle stand still and vehicle rolling direction. Vehicle motion state"}}, {leaf-element=VehMtnSt.VehMtnStChks, network-representation={base-type=UInt8_2, compu {identical; unit Unitless}, "Vehicle motion state information based on wheel speed sensors. Provides information about vehicle stand still and vehicle rolling direction. Checksum for vehicle motion state"}}, {leaf-element=VehMtnSt.VehMtnStCntr, network-representation={base-type=UInt4_2, compu {identical; unit Unitless}, "Vehicle motion state information based on wheel speed sensors. Provides information about vehicle stand still and vehicle rolling direction. Counter for vehicle motion state"}}], data-element=VehMtnSt, uses-end-to-end-protection=true, init-value=constant-reference=VehMtnSt_10}, required-interface=VehMtnSt_10
      CrashStsSafe: nonqueued-receiver-com-spec{composite-network-representations=[{leaf-element=CrashStsSafe.Sts, network-representation={base-type=CrashSts2_2, compu {0=CrashSts2_NoCrash, 1=CrashSts2_Crash; unit Unitless}, "Information if a crash has been detected by SRS."}}, {leaf-element=CrashStsSafe.Chks, network-representation={base-type=UInt8_2, compu {identical; unit Unitless}, "Checksum for E2E"}}, {leaf-element=CrashStsSafe.Cntr, network-representation={base-type=UInt4_2, compu {identical; unit Unitless}, "Counter for E2E"}}], data-element=CrashStsSafe, uses-end-to-end-protection=true, alive-timeout=1.0, init-value=constant-reference=CrashStsSafe_2}, required-interface=CrashStsSafe_2
      WhlMotSysTqAllwd: nonqueued-receiver-com-spec{composite-network-representations=[{leaf-element=WhlMotSysTqAllwd.WhlMotSysTqAllwd, network-representation={base-type=UInt2_2, compu {identical; unit Unitless}, "Indication if ERAD is allowed to apply propulsive or regenerative torque on wheels. Bit 0: Propulsive torque allowed Bit 1: Regenerative torque allowed"}}, {leaf-element=WhlMotSysTqAllwd.Chks, network-representation={base-type=UInt8_2, compu {identical; unit Unitless}, "Checksum for WhlMotSysTqAllwd"}}, {leaf-element=WhlMotSysTqAllwd.Cntr, network-representation={base-type=UInt4_2, compu {identical; unit Unitless}, "Counter for WhlMotSysTqAllwd"}}], data-element=WhlMotSysTqAllwd, uses-end-to-end-protection=true, alive-timeout=0.5, init-value=constant-reference=WhlMotSysTqAllwd_7}, required-interface=WhlMotSysTqAllwd_7
      HvBattSoc: nonqueued-receiver-com-spec{data-element=HvBattSoc, network-representation={base-type=Perc7_2, compu {phys=raw*0.05 for raw 0..2000; unit %}, "Actual state of charge of the Hv Battery."}, init-value=constant-reference=HvBattSoc_2}, required-interface=HvBattSoc_2
      HvBattUDynMinLim: nonqueued-receiver-com-spec{data-element=HvBattUDynMinLim, network-representation={base-type=HvU1_2, compu {phys=raw*0.25 for raw 0..2044; unit Volt}, "The pack voltage low limit of the Hv Battery, dynamically based on cell voltage distribution. At pack voltages below this limit, there is risk for contactor openeing due to too low cell voltage"}, init-value=constant-reference=HvBattUDynMinLim_4}, required-interface=HvBattUDynMinLim_4
      HvBattUDynMaxLim: nonqueued-receiver-com-spec{data-element=HvBattUDynMaxLim, network-representation={base-type=HvU1_2, compu {phys=raw*0.25 for raw 0..2044; unit Volt}, "The pack voltage high limit of the Hv Battery, dynamically based on cell voltage distribution. At pack voltages above this limit, there is risk for contactor openeing due to too high cell voltage."}, init-value=constant-reference=HvBattUDynMaxLim_4}, required-interface=HvBattUDynMaxLim_4
      HvBattUDc: nonqueued-receiver-com-spec{data-element=HvBattUDc, network-representation={base-type=HvU1_2, compu {phys=raw*0.25 for raw 0..2044; unit Volt}, "Actual Hv Battery pack voltage (measuered before contactors, i.e. always giving pack voltage)."}, init-value=constant-reference=HvBattUDc_3}, required-interface=HvBattUDc_3
      SpdRotlForWhlsAtAxleRe: nonqueued-receiver-com-spec{data-element=SpdRotlForWhlsAtAxleRe, network-representation={base-type=N1_2, compu {phys=raw*0.5 for raw 0..32767; unit rpm}, "Average angular velocity of rear wheels."}, init-value=constant-reference=SpdRotlForWhlsAtAxleRe_7}, required-interface=SpdRotlForWhlsAtAxleRe_7
      PLockParkReq: nonqueued-receiver-com-spec{data-element=PLockParkReq, network-representation={base-type=PLockParkRequest_1, compu-method=PLockParkRequest_1, "Park request to P-Lock."}, init-value=constant-reference=PLockParkReq_1}, required-interface=PLockParkReq_1
      DCChrgnHndlSts: nonqueued-receiver-com-spec{data-element=DCChrgnHndlSts, network-representation={base-type=OnBdChrgrHndlSts_2, compu-method=OnBdChrgrHndlSts_1, "Fast charging gun connect state"}, init-value=constant-reference=DCChrgnHndlSts_5}, required-interface=DCChrgnHndlSts_5
      OnBdChrgrHndlSts1: nonqueued-receiver-com-spec{data-element=OnBdChrgrHndlSts1, network-representation={base-type=OnBdChrgrHndlSts1_2, compu-method=OnBdChrgrHndlSts1_2, "Status of the Onboard Charger connection to the grid."}, init-value=constant-reference=OnBdChrgrHndlSts1_8}, required-interface=OnBdChrgrHndlSts1_8
    13 x port group, all with category=PARTIAL_NETWORKING:
      PropulsionStart
        outer-ports:
          IEM/ImobEngChk2
          IEM/ImobEngSts2
          IEM/WhlMotSysInvrT
          IEM/WhlMotSysMotT
          IEM/WhlMotSysCooltT
          IEM/WhlMotSysHeatPwrMax
          IEM/WhlMotSysHeatPwrAct
          IEM/WhlMotSysModSts
          IEM/WhlMotSysLimnIndcn
          IEM/WhlMotClrRdyReq
          IEM/WhlMotSysErrIndcnReq
          IEM/IemGeneric
          IEM/WhlMotSysIdc
          IEM/WhlMotSysUdc
          IEM/WhlMotSysSpdAct
          IEM/WhlMotSysTqAvl
          IEM/WhlMotSysTqEst
          IEM/PLockParkStsRe
          IEM/PLockFltIndcRe
          IEM/PLockFltLvlRe
          IEM/ImobEngMgrReq2
          IEM/EngSt1WdSts
          IEM/WhlMotSysModReq
          IEM/WhlMotSysActvDampgModReq
          IEM/WhlMotSysPwrLimMax
          IEM/WhlMotSysPwrLimMin
          IEM/PrpsnFbLimnIndcn
          IEM/DrvgCyc
          IEM/DCChrgnHndlSts
          IEM/OnBdChrgrHndlSts1
          IEM/HvSysRlySts
          IEM/EngSt1WdSts
          IEM/PrpsnFbLimnIndcn
          IEM/WhlMotSysActvDampgModReq
          IEM/WhlMotSysModReq
          IEM/WhlMotSysPwrLimMax
          IEM/WhlMotSysPwrLimMin
          IEM/WhlMotSysTqAllwd
          IEM/GearLvrIndcn
          IEM/HvBattSoc
          IEM/DrvgCyc
          IEM/EngSt1WdSts
          IEM/HvBattUDynMinLim
          IEM/HvBattUDynMaxLim
          IEM/HvBattUDc
          IEM/WhlMotSysTqReq
          IEM/PLockParkReq
      Immobilizer
        outer-ports:
          IEM/ImobEngChk2
          IEM/ImobEngSts2
          IEM/WhlMotSysHeatPwrMax
          IEM/WhlMotSysHeatPwrAct
          IEM/WhlMotSysModSts
          IEM/IemGeneric
          IEM/WhlMotSysIdc
          IEM/WhlMotSysUdc
          IEM/WhlMotSysSpdAct
          IEM/ImobEngMgrReq2
          IEM/EngSt1WdSts
          IEM/WhlMotSysModReq
          IEM/WhlMotSysActvDampgModReq
          IEM/WhlMotSysPwrLimMax
          IEM/WhlMotSysPwrLimMin
          IEM/EngSt1WdSts
          IEM/VehMtnSt
          IEM/WhlMotSysActvDampgModReq
          IEM/WhlMotSysModReq
          IEM/WhlMotSysPwrLimMax
          IEM/WhlMotSysPwrLimMin
          IEM/WhlMotSysTqAllwd
          IEM/GearLvrIndcn
          IEM/VehSpdLgt
          IEM/EngSt1WdSts
          IEM/WhlMotSysTqReq
          IEM/SpdRotlForWhlsAtAxleRe
      Diagnostics
        outer-ports:
          IEM/ImobEngChk2
          IEM/ImobEngSts2
          IEM/WhlMotSysCoolgReq
          IEM/WhlMotSysInvrT
          IEM/WhlMotSysMotT
          IEM/WhlMotSysCooltT
          IEM/WhlMotSysHeatPwrMax
          IEM/WhlMotSysHeatFdBck
          IEM/WhlMotSysHeatPwrAct
          IEM/WhlMotSysModSts
          IEM/WhlMotSysLimnIndcn
          IEM/WhlMotClrRdyReq
          IEM/WhlMotSysErrIndcnReq
          IEM/IemGeneric
          IEM/WhlMotSysIdc
          IEM/WhlMotSysUdc
          IEM/WhlMotCooltFlowMinReq
          IEM/WhlMotSysSpdAct
          IEM/WhlMotSysTqAvl
          IEM/WhlMotSysTqEst
          IEM/WhlMotSysSpdActSafe
          IEM/PLockParkStsRe
          IEM/PLockFltIndcRe
          IEM/PLockFltLvlRe
          IEM/ImobEngMgrReq2
          IEM/EngSt1WdSts
          IEM/VehSpdLgt
          IEM/HvSysRlySts
          IEM/CooltFlowForDtElec
          IEM/CooltTSigForDtElec
          IEM/WhlMotSysModReq
          IEM/WhlMotSysActvDampgModReq
          IEM/WhlMotSysPwrLimMax
          IEM/WhlMotSysPwrLimMin
          IEM/PrpsnFbLimnIndcn
          IEM/DrvgCyc
          IEM/CooltFlowForDtElec
          IEM/CooltTSigForDtElec
          IEM/RearHeatModEnad
          IEM/RearHeatPwrAllwd
          IEM/DCChrgnHndlSts
          IEM/OnBdChrgrHndlSts1
          IEM/PtTqAtAxleMaxReq
          IEM/HvSysRlySts
          IEM/EngSt1WdSts
          IEM/VehMtnSt
          IEM/PrpsnFbLimnIndcn
          IEM/CrashStsSafe
          IEM/WhlMotSysActvDampgModReq
          IEM/WhlMotSysModReq
          IEM/WhlMotSysPwrLimMax
          IEM/WhlMotSysPwrLimMin
          IEM/WhlMotSysTqAllwd
          IEM/GearLvrIndcn
          IEM/HvBattSoc
          IEM/DrvgCyc
          IEM/VehSpdLgt
          IEM/EngSt1WdSts
          IEM/HvBattUDynMinLim
          IEM/HvBattUDynMaxLim
          IEM/HvBattUDc
          IEM/WhlMotSysTqReq
          IEM/SpdRotlForWhlsAtAxleRe
          IEM/PLockParkReq
          IEM/VehSpdLgt
      VehicleModeManagement
        outer-ports:
          IEM/ImobEngChk2
          IEM/ImobEngSts2
          IEM/WhlMotSysCoolgReq
          IEM/WhlMotSysInvrT
          IEM/WhlMotSysMotT
          IEM/WhlMotSysCooltT
          IEM/WhlMotSysHeatPwrMax
          IEM/WhlMotSysHeatFdBck
          IEM/WhlMotSysHeatPwrAct
          IEM/WhlMotSysModSts
          IEM/WhlMotSysLimnIndcn
          IEM/WhlMotClrRdyReq
          IEM/WhlMotSysErrIndcnReq
          IEM/IemGeneric
          IEM/WhlMotSysIdc
          IEM/WhlMotSysUdc
          IEM/WhlMotCooltFlowMinReq
          IEM/WhlMotSysSpdAct
          IEM/WhlMotSysTqAvl
          IEM/WhlMotSysTqEst
          IEM/WhlMotSysSpdActSafe
          IEM/PLockParkStsRe
          IEM/PLockFltIndcRe
          IEM/PLockFltLvlRe
          IEM/ImobEngMgrReq2
          IEM/EngSt1WdSts
          IEM/VehSpdLgt
          IEM/HvSysRlySts
          IEM/CooltFlowForDtElec
          IEM/CooltTSigForDtElec
          IEM/WhlMotSysModReq
          IEM/WhlMotSysActvDampgModReq
          IEM/WhlMotSysPwrLimMax
          IEM/WhlMotSysPwrLimMin
          IEM/PrpsnFbLimnIndcn
          IEM/DrvgCyc
          IEM/CooltFlowForDtElec
          IEM/CooltTSigForDtElec
          IEM/RearHeatModEnad
          IEM/RearHeatPwrAllwd
          IEM/DCChrgnHndlSts
          IEM/OnBdChrgrHndlSts1
          IEM/PtTqAtAxleMaxReq
          IEM/HvSysRlySts
          IEM/EngSt1WdSts
          IEM/VehMtnSt
          IEM/PrpsnFbLimnIndcn
          IEM/CrashStsSafe
          IEM/WhlMotSysActvDampgModReq
          IEM/WhlMotSysModReq
          IEM/WhlMotSysPwrLimMax
          IEM/WhlMotSysPwrLimMin
          IEM/WhlMotSysTqAllwd
          IEM/GearLvrIndcn
          IEM/HvBattSoc
          IEM/DrvgCyc
          IEM/VehSpdLgt
          IEM/EngSt1WdSts
          IEM/HvBattUDynMinLim
          IEM/HvBattUDynMaxLim
          IEM/HvBattUDc
          IEM/WhlMotSysTqReq
          IEM/SpdRotlForWhlsAtAxleRe
          IEM/PLockParkReq
          IEM/VehSpdLgt
      ChargingHV
        outer-ports:
          IEM/WhlMotSysInvrT
          IEM/WhlMotSysMotT
          IEM/WhlMotSysCooltT
          IEM/WhlMotSysHeatPwrMax
          IEM/WhlMotSysHeatPwrAct
          IEM/WhlMotSysModSts
          IEM/WhlMotSysLimnIndcn
          IEM/WhlMotSysErrIndcnReq
          IEM/IemGeneric
          IEM/WhlMotSysIdc
          IEM/WhlMotSysUdc
          IEM/WhlMotSysSpdAct
          IEM/WhlMotSysTqAvl
          IEM/WhlMotSysTqEst
          IEM/WhlMotSysSpdActSafe
          IEM/PLockParkStsRe
          IEM/PLockFltIndcRe
          IEM/PLockFltLvlRe
          IEM/WhlMotSysModReq
          IEM/WhlMotSysActvDampgModReq
          IEM/WhlMotSysPwrLimMax
          IEM/WhlMotSysPwrLimMin
          IEM/PrpsnFbLimnIndcn
          IEM/DrvgCyc
          IEM/DCChrgnHndlSts
          IEM/OnBdChrgrHndlSts1
          IEM/HvSysRlySts
          IEM/EngSt1WdSts
          IEM/PrpsnFbLimnIndcn
          IEM/WhlMotSysActvDampgModReq
          IEM/WhlMotSysModReq
          IEM/WhlMotSysPwrLimMax
          IEM/WhlMotSysPwrLimMin
          IEM/WhlMotSysTqAllwd
          IEM/GearLvrIndcn
          IEM/HvBattSoc
          IEM/DrvgCyc
          IEM/EngSt1WdSts
          IEM/HvBattUDynMinLim
          IEM/HvBattUDynMaxLim
          IEM/HvBattUDc
          IEM/WhlMotSysTqReq
          IEM/PLockParkReq
      ParkingDrivingClimatization
        outer-ports:
          IEM/WhlMotSysCoolgReq
          IEM/WhlMotSysInvrT
          IEM/WhlMotSysMotT
          IEM/WhlMotSysCooltT
          IEM/WhlMotSysHeatPwrMax
          IEM/WhlMotSysHeatFdBck
          IEM/WhlMotSysHeatPwrAct
          IEM/WhlMotSysModSts
          IEM/WhlMotSysLimnIndcn
          IEM/WhlMotClrRdyReq
          IEM/WhlMotSysErrIndcnReq
          IEM/IemGeneric
          IEM/WhlMotSysIdc
          IEM/WhlMotSysUdc
          IEM/WhlMotCooltFlowMinReq
          IEM/WhlMotSysSpdAct
          IEM/WhlMotSysTqAvl
          IEM/WhlMotSysTqEst
          IEM/CooltFlowForDtElec
          IEM/CooltTSigForDtElec
          IEM/WhlMotSysModReq
          IEM/WhlMotSysActvDampgModReq
          IEM/WhlMotSysPwrLimMax
          IEM/WhlMotSysPwrLimMin
          IEM/PrpsnFbLimnIndcn
          IEM/DrvgCyc
          IEM/CooltFlowForDtElec
          IEM/CooltTSigForDtElec
          IEM/RearHeatModEnad
          IEM/RearHeatPwrAllwd
          IEM/DCChrgnHndlSts
          IEM/OnBdChrgrHndlSts1
          IEM/HvSysRlySts
          IEM/EngSt1WdSts
          IEM/VehMtnSt
          IEM/PrpsnFbLimnIndcn
          IEM/CrashStsSafe
          IEM/WhlMotSysActvDampgModReq
          IEM/WhlMotSysModReq
          IEM/WhlMotSysPwrLimMax
          IEM/WhlMotSysPwrLimMin
          IEM/WhlMotSysTqAllwd
          IEM/GearLvrIndcn
          IEM/HvBattSoc
          IEM/DrvgCyc
          IEM/VehSpdLgt
          IEM/EngSt1WdSts
          IEM/HvBattUDynMinLim
          IEM/HvBattUDynMaxLim
          IEM/HvBattUDc
          IEM/WhlMotSysTqReq
          IEM/SpdRotlForWhlsAtAxleRe
      TelematicsConnectivity
        outer-ports:
          IEM/WhlMotSysInvrT
          IEM/WhlMotSysMotT
          IEM/WhlMotSysCooltT
          IEM/WhlMotSysModSts
          IEM/WhlMotSysLimnIndcn
          IEM/IemGeneric
          IEM/WhlMotSysIdc
          IEM/WhlMotSysUdc
          IEM/WhlMotSysSpdAct
          IEM/WhlMotSysTqEst
          IEM/OnBdChrgrHndlSts1
      VehicleDriving
        outer-ports:
          IEM/WhlMotSysCoolgReq
          IEM/WhlMotSysInvrT
          IEM/WhlMotSysMotT
          IEM/WhlMotSysCooltT
          IEM/WhlMotSysHeatPwrMax
          IEM/WhlMotSysHeatFdBck
          IEM/WhlMotSysHeatPwrAct
          IEM/WhlMotSysModSts
          IEM/WhlMotSysLimnIndcn
          IEM/WhlMotClrRdyReq
          IEM/WhlMotSysErrIndcnReq
          IEM/IemGeneric
          IEM/WhlMotSysIdc
          IEM/WhlMotSysUdc
          IEM/WhlMotCooltFlowMinReq
          IEM/WhlMotSysSpdAct
          IEM/WhlMotSysTqAvl
          IEM/WhlMotSysTqEst
          IEM/WhlMotSysSpdActSafe
          IEM/PLockParkStsRe
          IEM/PLockFltIndcRe
          IEM/PLockFltLvlRe
          IEM/CooltFlowForDtElec
          IEM/CooltTSigForDtElec
          IEM/WhlMotSysModReq
          IEM/WhlMotSysActvDampgModReq
          IEM/WhlMotSysPwrLimMax
          IEM/WhlMotSysPwrLimMin
          IEM/PrpsnFbLimnIndcn
          IEM/DrvgCyc
          IEM/CooltFlowForDtElec
          IEM/CooltTSigForDtElec
          IEM/RearHeatModEnad
          IEM/RearHeatPwrAllwd
          IEM/DCChrgnHndlSts
          IEM/OnBdChrgrHndlSts1
          IEM/PtTqAtAxleMaxReq
          IEM/HvSysRlySts
          IEM/EngSt1WdSts
          IEM/VehMtnSt
          IEM/PrpsnFbLimnIndcn
          IEM/CrashStsSafe
          IEM/WhlMotSysActvDampgModReq
          IEM/WhlMotSysModReq
          IEM/WhlMotSysPwrLimMax
          IEM/WhlMotSysPwrLimMin
          IEM/WhlMotSysTqAllwd
          IEM/GearLvrIndcn
          IEM/HvBattSoc
          IEM/DrvgCyc
          IEM/VehSpdLgt
          IEM/EngSt1WdSts
          IEM/HvBattUDynMinLim
          IEM/HvBattUDynMaxLim
          IEM/HvBattUDc
          IEM/WhlMotSysTqReq
          IEM/SpdRotlForWhlsAtAxleRe
          IEM/PLockParkReq
          IEM/VehSpdLgt
      GlobalShortDuration
        outer-ports:
          IEM/WhlMotSysCooltT
          IEM/WhlMotSysModSts
          IEM/WhlMotSysLimnIndcn
          IEM/WhlMotSysUdc
          IEM/WhlMotSysSpdAct
          IEM/WhlMotSysSpdActSafe
          IEM/DCChrgnHndlSts
          IEM/OnBdChrgrHndlSts1
          IEM/HvSysRlySts
          IEM/VehMtnSt
          IEM/CrashStsSafe
          IEM/HvBattSoc
          IEM/VehSpdLgt
          IEM/HvBattUDynMinLim
          IEM/HvBattUDynMaxLim
          IEM/HvBattUDc
          IEM/SpdRotlForWhlsAtAxleRe
      HVEnergyStorage
        outer-ports:
          IEM/WhlMotSysCoolgReq
          IEM/WhlMotSysInvrT
          IEM/WhlMotSysMotT
          IEM/WhlMotSysCooltT
          IEM/WhlMotSysModSts
          IEM/WhlMotSysLimnIndcn
          IEM/WhlMotSysIdc
          IEM/WhlMotSysUdc
          IEM/WhlMotCooltFlowMinReq
          IEM/CooltFlowForDtElec
          IEM/CooltTSigForDtElec
          IEM/PrpsnFbLimnIndcn
          IEM/CooltFlowForDtElec
          IEM/CooltTSigForDtElec
          IEM/DCChrgnHndlSts
          IEM/HvSysRlySts
          IEM/PrpsnFbLimnIndcn
          IEM/HvBattSoc
          IEM/HvBattUDynMinLim
          IEM/HvBattUDynMaxLim
          IEM/HvBattUDc
      Crash
        outer-ports:
          IEM/WhlMotSysCoolgReq
          IEM/WhlMotSysInvrT
          IEM/WhlMotSysMotT
          IEM/WhlMotSysCooltT
          IEM/WhlMotSysModSts
          IEM/WhlMotSysLimnIndcn
          IEM/WhlMotClrRdyReq
          IEM/WhlMotSysErrIndcnReq
          IEM/WhlMotSysIdc
          IEM/WhlMotSysUdc
          IEM/WhlMotCooltFlowMinReq
          IEM/WhlMotSysSpdAct
          IEM/WhlMotSysTqEst
          IEM/WhlMotSysSpdActSafe
          IEM/CooltFlowForDtElec
          IEM/DrvgCyc
          IEM/CooltFlowForDtElec
          IEM/DCChrgnHndlSts
          IEM/PtTqAtAxleMaxReq
          IEM/HvSysRlySts
          IEM/CrashStsSafe
          IEM/HvBattSoc
          IEM/DrvgCyc
          IEM/HvBattUDynMinLim
          IEM/HvBattUDynMaxLim
          IEM/HvBattUDc
      InfotainmentPush: outer-ports=[IEM/WhlMotSysIdc, IEM/WhlMotSysUdc, IEM/WhlMotSysSpdAct, IEM/WhlMotSysTqEst, IEM/WhlMotSysSpdActSafe]
      Brake: outer-ports=[IEM/WhlMotSysIdc, IEM/WhlMotSysUdc, IEM/WhlMotSysSpdAct, IEM/WhlMotSysTqEst, IEM/WhlMotSysSpdActSafe]
    component IEMDTCS: type=IEMDTCS
    component IEMHOST: type=IEMHOST
    delegate IEMDTCS.DmcStsRearToEsc <-> outer port IEM/DmcStsRearToEsc
    delegate IEMHOST.ImobEngChk2 <-> outer port IEM/ImobEngChk2
    delegate IEMHOST.ImobEngSts2 <-> outer port IEM/ImobEngSts2
    delegate IEMHOST.IEMTestFr{1..3} <-> outer port IEM/IEMTestFr{1..3}
    delegate IEMHOST.WhlMotSysCoolgReq <-> outer port IEM/WhlMotSysCoolgReq
    delegate IEMHOST.WhlMotSysInvrT <-> outer port IEM/WhlMotSysInvrT
    delegate IEMHOST.WhlMotSysMotT <-> outer port IEM/WhlMotSysMotT
    delegate IEMHOST.WhlMotSysCooltT <-> outer port IEM/WhlMotSysCooltT
    delegate IEMHOST.WhlMotSysHeatPwrMax <-> outer port IEM/WhlMotSysHeatPwrMax
    delegate IEMHOST.WhlMotSysHeatFdBck <-> outer port IEM/WhlMotSysHeatFdBck
    delegate IEMHOST.WhlMotSysHeatPwrAct <-> outer port IEM/WhlMotSysHeatPwrAct
    delegate IEMHOST.WhlMotSysModSts <-> outer port IEM/WhlMotSysModSts
    delegate IEMHOST.WhlMotSysLimnIndcn <-> outer port IEM/WhlMotSysLimnIndcn
    delegate IEMHOST.WhlMotClrRdyReq <-> outer port IEM/WhlMotClrRdyReq
    delegate IEMHOST.WhlMotSysErrIndcnReq <-> outer port IEM/WhlMotSysErrIndcnReq
    delegate IEMHOST.IemGeneric <-> outer port IEM/IemGeneric
    delegate IEMHOST.WhlMotSysIdc <-> outer port IEM/WhlMotSysIdc
    delegate IEMHOST.WhlMotSysUdc <-> outer port IEM/WhlMotSysUdc
    delegate IEMHOST.WhlMotCooltFlowMinReq <-> outer port IEM/WhlMotCooltFlowMinReq
    delegate IEMHOST.WhlMotSysSpdAct <-> outer port IEM/WhlMotSysSpdAct
    delegate IEMHOST.WhlMotSysTqAvl <-> outer port IEM/WhlMotSysTqAvl
    delegate IEMHOST.WhlMotSysTqEst <-> outer port IEM/WhlMotSysTqEst
    delegate IEMHOST.WhlMotSysSpdActSafe <-> outer port IEM/WhlMotSysSpdActSafe
    delegate IEMHOST.PLockParkStsRe <-> outer port IEM/PLockParkStsRe
    delegate IEMHOST.PLockFltIndcRe <-> outer port IEM/PLockFltIndcRe
    delegate IEMHOST.PLockFltLvlRe <-> outer port IEM/PLockFltLvlRe
    delegate IEMDTCS.WhlMotSysTqReq <-> outer port IEM/WhlMotSysTqReq
    delegate IEMHOST.WhlMotSysTqReq <-> outer port IEM/WhlMotSysTqReq
    delegate IEMDTCS.GearLvrIndcn <-> outer port IEM/GearLvrIndcn
    delegate IEMHOST.GearLvrIndcn <-> outer port IEM/GearLvrIndcn
    delegate IEMDTCS.StcStsToDmc <-> outer port IEM/StcStsToDmc
    delegate IEMDTCS.EscVariantToDmc <-> outer port IEM/EscVariantToDmc
    delegate IEMHOST.CarTiGlb <-> outer port IEM/CarTiGlb
    delegate IEMHOST.VehModMngtGlbSafe1 <-> outer port IEM/VehModMngtGlbSafe1
    delegate IEMHOST.VehBattU <-> outer port IEM/VehBattU
    delegate IEMHOST.BkpOfDstTrvld <-> outer port IEM/BkpOfDstTrvld
    delegate IEMHOST.VehCfgPrm <-> outer port IEM/VehCfgPrm
    delegate IEMHOST.VehCfgPrmExt <-> outer port IEM/VehCfgPrmExt
    delegate IEMHOST.ImobEngMgrReq2 <-> outer port IEM/ImobEngMgrReq2
    delegate IEMHOST.EngSt1WdSts <-> outer port IEM/EngSt1WdSts
    delegate IEMHOST.VehSpdLgt <-> outer port IEM/VehSpdLgt
    delegate IEMHOST.HvSysRlySts <-> outer port IEM/HvSysRlySts
    delegate IEMHOST.CooltFlowForDtElec <-> outer port IEM/CooltFlowForDtElec
    delegate IEMHOST.CooltTSigForDtElec <-> outer port IEM/CooltTSigForDtElec
    delegate IEMHOST.WhlMotSysModReq <-> outer port IEM/WhlMotSysModReq
    delegate IEMHOST.WhlMotSysActvDampgModReq <-> outer port IEM/WhlMotSysActvDampgModReq
    delegate IEMHOST.WhlMotSysPwrLimMax <-> outer port IEM/WhlMotSysPwrLimMax
    delegate IEMHOST.WhlMotSysPwrLimMin <-> outer port IEM/WhlMotSysPwrLimMin
    delegate IEMHOST.PrpsnFbLimnIndcn <-> outer port IEM/PrpsnFbLimnIndcn
    delegate IEMHOST.DrvgCyc <-> outer port IEM/DrvgCyc
    delegate IEMHOST.RearHeatModEnad <-> outer port IEM/RearHeatModEnad
    delegate IEMHOST.RearHeatPwrAllwd <-> outer port IEM/RearHeatPwrAllwd
    delegate IEMHOST.PtTqAtAxleMaxReq <-> outer port IEM/PtTqAtAxleMaxReq
    delegate IEMHOST.VehMtnSt <-> outer port IEM/VehMtnSt
    delegate IEMHOST.CrashStsSafe <-> outer port IEM/CrashStsSafe
    delegate IEMHOST.WhlMotSysTqAllwd <-> outer port IEM/WhlMotSysTqAllwd
    delegate IEMHOST.HvBattSoc <-> outer port IEM/HvBattSoc
    delegate IEMHOST.HvBattUDynMinLim <-> outer port IEM/HvBattUDynMinLim
    delegate IEMHOST.HvBattUDynMaxLim <-> outer port IEM/HvBattUDynMaxLim
    delegate IEMHOST.HvBattUDc <-> outer port IEM/HvBattUDc
    delegate IEMHOST.SpdRotlForWhlsAtAxleRe <-> outer port IEM/SpdRotlForWhlsAtAxleRe
    delegate IEMHOST.PLockParkReq <-> outer port IEM/PLockParkReq
    delegate IEMHOST.DCChrgnHndlSts <-> outer port IEM/DCChrgnHndlSts
    delegate IEMHOST.OnBdChrgrHndlSts1 <-> outer port IEM/OnBdChrgrHndlSts1
    connect IEMHOST.WhlMotSysSpdActSafe -> IEMDTCS.WhlMotSysSpdActSafe
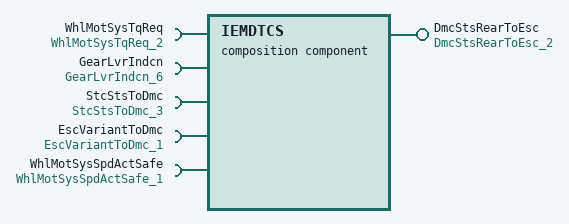
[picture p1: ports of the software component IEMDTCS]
  composition sw component type IEMDTCS
    provide port DmcStsRearToEsc: nonqueued-sender-com-spec{composite-network-representations=[{leaf-element=DmcStsRearToEsc.DmcSts, network-representation={base-type=DMC_1, compu {0=DMC_Init, 1=DMC_On, 2=DMC_Off, 3=DMC_Fault; unit Unitless}, "DmcSts"}}, {leaf-element=DmcStsRearToEsc.DmcActAppTarTq, network-representation={base-type=Tq35_1, compu {phys=raw for raw -30000..30000; unit NewtonMeter}, "DMCActAppTarTq"}}, {leaf-element=DmcStsRearToEsc.Cntr, network-representation={base-type=UInt4_2, compu {identical; unit Unitless}, "Cntr"}}, {leaf-element=DmcStsRearToEsc.Chks, network-representation={base-type=UInt8_2, compu {identical; unit Unitless}, "Chks"}}, {leaf-element=DmcStsRearToEsc.DmcSWInfo, network-representation={base-type=UInt16_2, compu {identical; unit Unitless}, "DmCSWinformation"}}], data-element=DmcStsRearToEsc, uses-end-to-end-protection=true, init-value=constant-reference=DmcStsRearToEsc_2}, provided-interface=DmcStsRearToEsc_2
    5 x require port:
      WhlMotSysTqReq: nonqueued-receiver-com-spec{data-element=WhlMotSysTqReq, network-representation={base-type=HvTq1_2, compu {phys=raw*4-8188 for raw 0..4095; unit NewtonMeter}, "Requested electric motor torque referred to the wheel axle. The torque is positive in the forward rotation direction."}, init-value=constant-reference=WhlMotSysTqReq_2}, required-interface=WhlMotSysTqReq_2
      GearLvrIndcn: nonqueued-receiver-com-spec{data-element=GearLvrIndcn, network-representation={base-type=GearLvrIndcn2_2, compu-method=GearLvrIndcn2_1, "Gear lever indication (drivetrain position) to the driver. If drivetrain position is not possible to decide signal is set to undefined. Valid for automatic vehicles."}, init-value=constant-reference=GearLvrIndcn_6}, required-interface=GearLvrIndcn_6
      StcStsToDmc: nonqueued-receiver-com-spec{composite-network-representations=[{leaf-element=StcStsToDmc.StcStsToDmcFrnt, network-representation={base-type=ModeDMC_1, compu {0=ModeDMC_Off, 1=ModeDMC_Rpm, 2=ModeDMC_Trq; unit Unitless}, "StcSts to Dmc frint"}}, {leaf-element=StcStsToDmc.StcStsToDmcRear, network-representation={base-type=ModeDMC_1, compu {0=ModeDMC_Off, 1=ModeDMC_Rpm, 2=ModeDMC_Trq; unit Unitless}, "StcSts to DMC Rear"}}, {leaf-element=StcStsToDmc.EngRotTarSpdDMCFrnt, network-representation={base-type=UInt16_2, compu {identical; unit Unitless}, "EngRoTarSpdDMC frint"}}, {leaf-element=StcStsToDmc.EngRotTarSpdDMCRear, network-representation={base-type=UInt16_2, compu {identical; unit Unitless}, "EngRoTarSpdDMC rear"}}, {leaf-element=StcStsToDmc.Chks, network-representation={base-type=UInt8_2, compu {identical; unit Unitless}, "Chks"}}, {leaf-element=StcStsToDmc.Cntr, network-representation={base-type=UInt4_2, compu {identical; unit Unitless}, "Cntr"}}], data-element=StcStsToDmc, uses-end-to-end-protection=true, init-value=constant-reference=StcStsToDmc_3}, required-interface=StcStsToDmc_3
      EscVariantToDmc: nonqueued-receiver-com-spec{composite-network-representations=[{leaf-element=EscVariantToDmc.EscVariantToDmc, network-representation={base-type=UInt8_2, compu {identical; unit Unitless}, "Esc Variant"}}, {leaf-element=EscVariantToDmc.Chks, network-representation={base-type=UInt8_2, compu {identical; unit Unitless}, "Chks"}}, {leaf-element=EscVariantToDmc.Cntr, network-representation={base-type=UInt4_2, compu {identical; unit Unitless}, "Cntr"}}], data-element=EscVariantToDmc, uses-end-to-end-protection=true, init-value=constant-reference=EscVariantToDmc_1}, required-interface=EscVariantToDmc_1
      WhlMotSysSpdActSafe: nonqueued-receiver-com-spec{composite-network-representations=[{leaf-element=WhlMotSysSpdActSafe.IsgSpdWSgnTyp, network-representation={base-type=IsgSpdWSgnTyp_2, compu {phys=raw for raw -16384..16383; unit rpm}, "Safe EM motor shaft speed."}}, {leaf-element=WhlMotSysSpdActSafe.Chks, network-representation={base-type=UInt8_2, compu {identical; unit Unitless}, "checksum"}}, {leaf-element=WhlMotSysSpdActSafe.Cntr, network-representation={base-type=UInt4_2, compu {identical; unit Unitless}, "counter"}}, {leaf-element=WhlMotSysSpdActSafe.Qf, network-representation={base-type=GenQf1_2, compu-method=GenQf1_1, "quality factor"}}], data-element=WhlMotSysSpdActSafe, uses-end-to-end-protection=true, init-value=constant-reference=WhlMotSysSpdActSafe_1}, required-interface=WhlMotSysSpdActSafe_1
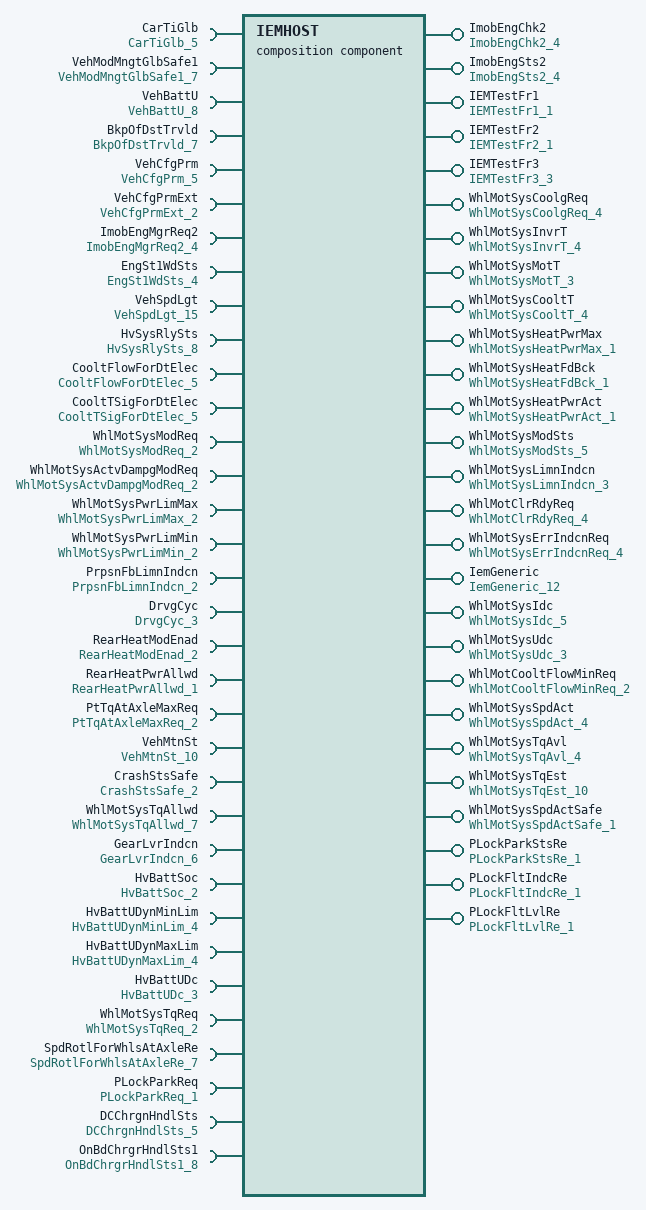
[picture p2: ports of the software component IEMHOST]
  composition sw component type IEMHOST
    27 x provide port:
      ImobEngChk2: nonqueued-sender-com-spec{composite-network-representations=[{leaf-element=ImobEngChk2.ImobEngChkSts, network-representation={base-type=AvlSts2_2, compu {0=AvlSts2_NotAvl, 1=AvlSts2_Avl; unit Unitless}, "Message from IEM to CEM that challenge is available and 7 bytes of challenge. Message to CEM Challenge available"}}, {leaf-element=ImobEngChk2.ImobEngDataChk0, network-representation={base-type=UInt8_2, compu {identical; unit Unitless}, "Message from IEM to CEM that challenge is available and 7 bytes of challenge. Byte 0"}}, {leaf-element=ImobEngChk2.ImobEngDataChk1, network-representation={base-type=UInt8_2, compu {identical; unit Unitless}, "Message from IEM to CEM that challenge is available and 7 bytes of challenge. Byte 1"}}, {leaf-element=ImobEngChk2.ImobEngDataChk2, network-representation={base-type=UInt8_2, compu {identical; unit Unitless}, "Message from IEM to CEM that challenge is available and 7 bytes of challenge. Byte 2"}}, {leaf-element=ImobEngChk2.ImobEngDataChk3, network-representation={base-type=UInt8_2, compu {identical; unit Unitless}, "Message from IEM to CEM that challenge is available and 7 bytes of challenge. Byte 3"}}, {leaf-element=ImobEngChk2.ImobEngDataChk4, network-representation={base-type=UInt8_2, compu {identical; unit Unitless}, "Message from IEM to CEM that challenge is available and 7 bytes of challenge. Byte 4"}}, {leaf-element=ImobEngChk2.ImobEngDataChk5, network-representation={base-type=UInt8_2, compu {identical; unit Unitless}, "Message from IEM to CEM that challenge is available and 7 bytes of challenge. Byte 5"}}, {leaf-element=ImobEngChk2.ImobEngDataChk6, network-representation={base-type=UInt8_2, compu {identical; unit Unitless}, "Message from IEM to CEM that challenge is available and 7 bytes of challenge. Byte 6"}}], data-element=ImobEngChk2, init-value=constant-reference=ImobEngChk2_4}, provided-interface=ImobEngChk2_4
      ImobEngSts2: nonqueued-sender-com-spec{data-element=ImobEngSts2, network-representation={base-type=ImobSts_2, compu-method=ImobSts_1, "IEM CEM message immo status. Can be undefined, immobilised, motive mobilised or non motive mobilised."}, init-value=constant-reference=ImobEngSts2_4}, provided-interface=ImobEngSts2_4
      IEMTestFr1: nonqueued-sender-com-spec{composite-network-representations=[{leaf-element=IEMTestFr1.Byte0, network-representation={base-type=UInt8_2, compu {identical; unit Unitless}, "DTC1 status"}}, {leaf-element=IEMTestFr1.Byte1, network-representation={base-type=UInt8_2, compu {identical; unit Unitless}, "DTC1 low byte"}}, {leaf-element=IEMTestFr1.Byte2, network-representation={base-type=UInt8_2, compu {identical; unit Unitless}, "DTC1 middle byte"}}, {leaf-element=IEMTestFr1.Byte3, network-representation={base-type=UInt8_2, compu {identical; unit Unitless}, "DTC1 high byte"}}, {leaf-element=IEMTestFr1.Byte4, network-representation={base-type=UInt8_2, compu {identical; unit Unitless}, "DTC2 status"}}, {leaf-element=IEMTestFr1.Byte5, network-representation={base-type=UInt8_2, compu {identical; unit Unitless}, "DTC2 low byte"}}, {leaf-element=IEMTestFr1.Byte6, network-representation={base-type=UInt8_2, compu {identical; unit Unitless}, "DTC2 middle byte"}}, {leaf-element=IEMTestFr1.Byte7, network-representation={base-type=UInt8_2, compu {identical; unit Unitless}, "DTC2 high byte"}}], data-element=IEMTestFr1, init-value=constant-reference=IEMTestFr1_1}, provided-interface=IEMTestFr1_1
      IEMTestFr2: nonqueued-sender-com-spec{composite-network-representations=[{leaf-element=IEMTestFr2.Byte0, network-representation={base-type=UInt8_2, compu {identical; unit Unitless}, "DTC1 status"}}, {leaf-element=IEMTestFr2.Byte1, network-representation={base-type=UInt8_2, compu {identical; unit Unitless}, "DTC1 low byte"}}, {leaf-element=IEMTestFr2.Byte2, network-representation={base-type=UInt8_2, compu {identical; unit Unitless}, "DTC1 middle byte"}}, {leaf-element=IEMTestFr2.Byte3, network-representation={base-type=UInt8_2, compu {identical; unit Unitless}, "DTC1 high byte"}}, {leaf-element=IEMTestFr2.Byte4, network-representation={base-type=UInt8_2, compu {identical; unit Unitless}, "DTC2 status"}}, {leaf-element=IEMTestFr2.Byte5, network-representation={base-type=UInt8_2, compu {identical; unit Unitless}, "DTC2 low byte"}}, {leaf-element=IEMTestFr2.Byte6, network-representation={base-type=UInt8_2, compu {identical; unit Unitless}, "DTC2 middle byte"}}, {leaf-element=IEMTestFr2.Byte7, network-representation={base-type=UInt8_2, compu {identical; unit Unitless}, "DTC2 high byte"}}], data-element=IEMTestFr2, init-value=constant-reference=IEMTestFr2_1}, provided-interface=IEMTestFr2_1
      IEMTestFr3: nonqueued-sender-com-spec{composite-network-representations=[{leaf-element=IEMTestFr3.Byte0, network-representation={base-type=UInt8_2, compu {identical; unit Unitless}, "Info0"}}, {leaf-element=IEMTestFr3.Byte1, network-representation={base-type=UInt8_2, compu {identical; unit Unitless}, "Info1"}}, {leaf-element=IEMTestFr3.Byte2, network-representation={base-type=UInt8_2, compu {identical; unit Unitless}, "Info2"}}, {leaf-element=IEMTestFr3.Byte3, network-representation={base-type=UInt8_2, compu {identical; unit Unitless}, "Info3"}}, {leaf-element=IEMTestFr3.Byte4, network-representation={base-type=UInt8_2, compu {identical; unit Unitless}, "Info4"}}, {leaf-element=IEMTestFr3.Byte5, network-representation={base-type=UInt8_2, compu {identical; unit Unitless}, "Info5"}}, {leaf-element=IEMTestFr3.Byte6, network-representation={base-type=UInt8_2, compu {identical; unit Unitless}, "Info6"}}, {leaf-element=IEMTestFr3.Byte7, network-representation={base-type=UInt8_2, compu {identical; unit Unitless}, "Info7"}}], data-element=IEMTestFr3, init-value=constant-reference=IEMTestFr3_3}, provided-interface=IEMTestFr3_3
      WhlMotSysCoolgReq: nonqueued-sender-com-spec{data-element=WhlMotSysCoolgReq, network-representation={base-type=HvCoolg1_2, compu-method=HvCoolg1_1, "Signal to request increased cooling to Erad and IEM.Request is in 3 steps of increased cooling."}, init-value=constant-reference=WhlMotSysCoolgReq_4}, provided-interface=WhlMotSysCoolgReq_4
      WhlMotSysInvrT: nonqueued-sender-com-spec{data-element=WhlMotSysInvrT, network-representation={base-type=T3_2, compu {phys=raw-50 for raw 0..250; unit degC}, "The inverter temperature measured in the IEM."}, init-value=constant-reference=WhlMotSysInvrT_4}, provided-interface=WhlMotSysInvrT_4
      WhlMotSysMotT: nonqueued-sender-com-spec{data-element=WhlMotSysMotT, network-representation={base-type=T3_2, compu {phys=raw-50 for raw 0..250; unit degC}, "The temperature of motor"}, init-value=constant-reference=WhlMotSysMotT_3}, provided-interface=WhlMotSysMotT_3
      WhlMotSysCooltT: nonqueued-sender-com-spec{data-element=WhlMotSysCooltT, network-representation={base-type=HvT1_3, compu {phys=raw-40 for raw 0..255; unit degC}, "Measured coolant temperature in rear axle inverter in degC"}, init-value=constant-reference=WhlMotSysCooltT_4}, provided-interface=WhlMotSysCooltT_4
      WhlMotSysHeatPwrMax: nonqueued-sender-com-spec{data-element=WhlMotSysHeatPwrMax, network-representation={base-type=IsgHeatPwr_1, compu {phys=raw*50 for raw 0..255; unit W}, "The electrical power required by the current maximum heating power of the rear motor"}, init-value=constant-reference=WhlMotSysHeatPwrMax_1}, provided-interface=WhlMotSysHeatPwrMax_1
      WhlMotSysHeatFdBck: nonqueued-sender-com-spec{data-element=WhlMotSysHeatFdBck, network-representation={base-type=WhlMotSysHeatFdBck_1, compu-method=WhlMotSysHeatFdBck_1, "The feedback of the rear motor to responds to the heating enabling signal of ECM"}, init-value=constant-reference=WhlMotSysHeatFdBck_1}, provided-interface=WhlMotSysHeatFdBck_1
      WhlMotSysHeatPwrAct: nonqueued-sender-com-spec{data-element=WhlMotSysHeatPwrAct, network-representation={base-type=IsgHeatPwr_1, compu {phys=raw*50 for raw 0..255; unit W}, "The actual electrical energy consumption for active heating of rear motor"}, init-value=constant-reference=WhlMotSysHeatPwrAct_1}, provided-interface=WhlMotSysHeatPwrAct_1
      WhlMotSysModSts: nonqueued-sender-com-spec{data-element=WhlMotSysModSts, network-representation={base-type=WhlMotSysModStsTyp2_2, compu-method=WhlMotSysModStsTyp2_2, "Reflects the current operating mode of the IEM."}, init-value=constant-reference=WhlMotSysModSts_5}, provided-interface=WhlMotSysModSts_5
      WhlMotSysLimnIndcn: nonqueued-sender-com-spec{data-element=WhlMotSysLimnIndcn, network-representation={base-type=UInt16_2, compu {identical; unit Unitless}, "The limitation indication of derating conditions"}, init-value=constant-reference=WhlMotSysLimnIndcn_3}, provided-interface=WhlMotSysLimnIndcn_3
      WhlMotClrRdyReq: nonqueued-sender-com-spec{data-element=WhlMotClrRdyReq, network-representation={base-type=OnOff1_2, compu {0=OnOff1_Off, 1=OnOff1_On; unit Unitless}, "WhlMotClrRdyReq"}, init-value=constant-reference=WhlMotClrRdyReq_4}, provided-interface=WhlMotClrRdyReq_4
      WhlMotSysErrIndcnReq: nonqueued-sender-com-spec{data-element=WhlMotSysErrIndcnReq, network-representation={base-type=OnOff1_2, compu {0=OnOff1_Off, 1=OnOff1_On; unit Unitless}, "WhlMotSysErrIndcnReq"}, init-value=constant-reference=WhlMotSysErrIndcnReq_4}, provided-interface=WhlMotSysErrIndcnReq_4
      IemGeneric: nonqueued-sender-com-spec{composite-network-representations=[{leaf-element=IemGeneric.EMQnty, network-representation={base-type=UInt4_2, compu {identical; unit Unitless}, "Quantity of electric motor"}}, {leaf-element=IemGeneric.EMSeqNr, network-representation={base-type=UInt4_2, compu {identical; unit Unitless}, "Sequence number of electric motor"}}, {leaf-element=IemGeneric.DTCSts, network-representation={base-type=UInt8_2, compu {identical; unit Unitless}, "DTC Status"}}, {leaf-element=IemGeneric.DTCLow, network-representation={base-type=UInt8_2, compu {identical; unit Unitless}, "DTC low byte for non OBD"}}, {leaf-element=IemGeneric.DTCMid, network-representation={base-type=UInt8_2, compu {identical; unit Unitless}, "DTC middle byte for non OBD DTC low byte for OBD"}}, {leaf-element=IemGeneric.DTCHig, network-representation={base-type=UInt8_2, compu {identical; unit Unitless}, "DTC high byte for non OBD or OBD"}}, {leaf-element=IemGeneric.TypeInfo, network-representation={base-type=UInt4_2, compu {identical; unit Unitless}, "Indicate different EDS suppliers. OEM defines this value. 0=not defined 1=PMA1 VseA, with ratio=10.134 2=PMA1 Nidec,with ratio=10.294 3=PMA1 VREMT,with ratio=11.56 4=SPAL Scheaffler,with ratio=9.071 5=SPA Simens, with ratio=10.008 6=PMA2 VREMT,with ratio=11.209 7=EPA ZF,with radio=9.187 8=EPA Polestar,with 2-gear ratio=7.155 and 13.645 9=PMA2 UAES,with ratio=11.067"}}, {leaf-element=IemGeneric.MotTAlrmSt, network-representation={base-type=AlrmSt_2, compu {0=AlrmSt_Disarmd, 1=AlrmSt_Armd, 2=AlrmSt_Actv; unit Unitless}, "Motor temperature alarm status"}}, {leaf-element=IemGeneric.InvrtTAlrmSt, network-representation={base-type=AlrmSt_2, compu {0=AlrmSt_Disarmd, 1=AlrmSt_Armd, 2=AlrmSt_Actv; unit Unitless}, "Inverter temperature alarm status"}}, {leaf-element=IemGeneric.FltAlrmSt, network-representation={base-type=AlrmSt_2, compu {0=AlrmSt_Disarmd, 1=AlrmSt_Armd, 2=AlrmSt_Actv; unit Unitless}, "Fault alarm status"}}, {leaf-element=IemGeneric.SpdAlrmSt, network-representation={base-type=AlrmSt_2, compu {0=AlrmSt_Disarmd, 1=AlrmSt_Armd, 2=AlrmSt_Actv; unit Unitless}, "Over speed alarm status"}}, {leaf-element=IemGeneric.IacAlrmSt, network-representation={base-type=AlrmSt_2, compu {0=AlrmSt_Disarmd, 1=AlrmSt_Armd, 2=AlrmSt_Actv; unit Unitless}, "3 Phase current alarm status"}}, {leaf-element=IemGeneric.UDcAlrmSt, network-representation={base-type=AlrmSt_2, compu {0=AlrmSt_Disarmd, 1=AlrmSt_Armd, 2=AlrmSt_Actv; unit Unitless}, "High voltage alarm status"}}, {leaf-element=IemGeneric.RslAlrmSt, network-representation={base-type=AlrmSt_2, compu {0=AlrmSt_Disarmd, 1=AlrmSt_Armd, 2=AlrmSt_Actv; unit Unitless}, "Resolver fault alarm status"}}, {leaf-element=IemGeneric.ADAlrmSt, network-representation={base-type=AlrmSt_2, compu {0=AlrmSt_Disarmd, 1=AlrmSt_Armd, 2=AlrmSt_Actv; unit Unitless}, "Active Discharge fault alarm status"}}, {leaf-element=IemGeneric.ModStatusRms, network-representation={base-type=ModStatusRms_2, compu-method=ModStatusRms_2, "Motor status for RMS monitor"}}], data-element=IemGeneric, init-value=constant-reference=IemGeneric_12}, provided-interface=IemGeneric_12
      WhlMotSysIdc: nonqueued-sender-com-spec{data-element=WhlMotSysIdc, network-representation={base-type=Ampr1_1, compu {phys=raw*0.1-818.8 for raw 0..16380; unit A}, "DC current measured in the IEM."}, init-value=constant-reference=WhlMotSysIdc_5}, provided-interface=WhlMotSysIdc_5
      WhlMotSysUdc: nonqueued-sender-com-spec{data-element=WhlMotSysUdc, network-representation={base-type=HvU1_2, compu {phys=raw*0.25 for raw 0..2044; unit Volt}, "The DC voltage of rear motor"}, init-value=constant-reference=WhlMotSysUdc_3}, provided-interface=WhlMotSysUdc_3
      WhlMotCooltFlowMinReq: nonqueued-sender-com-spec{data-element=WhlMotCooltFlowMinReq, network-representation={base-type=CooltFlowForDtElec1_2, compu {phys=raw*0.01 for raw 0..1023; unit L / min}, "Minimum coolant flow required by rear wheel motor"}, init-value=constant-reference=WhlMotCooltFlowMinReq_2}, provided-interface=WhlMotCooltFlowMinReq_2
      WhlMotSysSpdAct: nonqueued-sender-com-spec{data-element=WhlMotSysSpdAct, network-representation={base-type=IsgSpdWSgnTyp_2, compu {phys=raw for raw -16384..16383; unit rpm}, "The actual rotational speed of rear motor"}, init-value=constant-reference=WhlMotSysSpdAct_4}, provided-interface=WhlMotSysSpdAct_4
      WhlMotSysTqAvl: nonqueued-sender-com-spec{composite-network-representations=[{leaf-element=WhlMotSysTqAvl.TqAvlMax, network-representation={base-type=HvTq1_2, compu {phys=raw*4-8188 for raw 0..4095; unit NewtonMeter}, "Max available torque"}}, {leaf-element=WhlMotSysTqAvl.TqAvlMin, network-representation={base-type=HvTq1_2, compu {phys=raw*4-8188 for raw 0..4095; unit NewtonMeter}, "Min available torque"}}], data-element=WhlMotSysTqAvl, init-value=constant-reference=WhlMotSysTqAvl_4}, provided-interface=WhlMotSysTqAvl_4
      WhlMotSysTqEst: nonqueued-sender-com-spec{composite-network-representations=[{leaf-element=WhlMotSysTqEst.Cntr, network-representation={base-type=UInt4_2, compu {identical; unit Unitless}, "Counter of estimation torque"}}, {leaf-element=WhlMotSysTqEst.Chks, network-representation={base-type=UInt8_2, compu {identical; unit Unitless}, "Checksum of estimation torque"}}, {leaf-element=WhlMotSysTqEst.QualityFactor, network-representation={base-type=QualityFactor_2, compu-method=QualityFactor_1, "Quality factor of estimation torque"}}, {leaf-element=WhlMotSysTqEst.IsgTqAct, network-representation={base-type=Tq34_1, compu {phys=raw-8188 for raw 0..16380; unit NewtonMeter}, "Estimation torque of Rear Axle Control"}}], data-element=WhlMotSysTqEst, uses-end-to-end-protection=true, init-value=constant-reference=WhlMotSysTqEst_10}, provided-interface=WhlMotSysTqEst_10
      WhlMotSysSpdActSafe: nonqueued-sender-com-spec{composite-network-representations=[{leaf-element=WhlMotSysSpdActSafe.IsgSpdWSgnTyp, network-representation={base-type=IsgSpdWSgnTyp_2, compu {phys=raw for raw -16384..16383; unit rpm}, "Safe EM motor shaft speed."}}, {leaf-element=WhlMotSysSpdActSafe.Chks, network-representation={base-type=UInt8_2, compu {identical; unit Unitless}, "checksum"}}, {leaf-element=WhlMotSysSpdActSafe.Cntr, network-representation={base-type=UInt4_2, compu {identical; unit Unitless}, "counter"}}, {leaf-element=WhlMotSysSpdActSafe.Qf, network-representation={base-type=GenQf1_2, compu-method=GenQf1_1, "quality factor"}}], data-element=WhlMotSysSpdActSafe, uses-end-to-end-protection=true, init-value=constant-reference=WhlMotSysSpdActSafe_1}, provided-interface=WhlMotSysSpdActSafe_1
      PLockParkStsRe: nonqueued-sender-com-spec{data-element=PLockParkStsRe, network-representation={base-type=ParkSts_1, compu-method=ParkSts_1, "P-lock status (IEM)"}, init-value=constant-reference=PLockParkStsRe_1}, provided-interface=PLockParkStsRe_1
      PLockFltIndcRe: nonqueued-sender-com-spec{data-element=PLockFltIndcRe, network-representation={base-type=FltIndcn_1, compu-method=FltIndcn_1, "Fault indication signal for P-lock, for rear electric drive"}, init-value=constant-reference=PLockFltIndcRe_1}, provided-interface=PLockFltIndcRe_1
      PLockFltLvlRe: nonqueued-sender-com-spec{data-element=PLockFltLvlRe, network-representation={base-type=FltLvl_1, compu {0=FltLvl_NoFlt, 1=FltLvl_FltLvl1, 2=FltLvl_FltLvl2; unit Unitless}, "P-lock fault level, for rear electric drive."}, init-value=constant-reference=PLockFltLvlRe_1}, provided-interface=PLockFltLvlRe_1
    34 x require port:
      CarTiGlb: nonqueued-receiver-com-spec{data-element=CarTiGlb, network-representation={base-type=CarTiGlb_2, compu {phys=raw*0.1 for raw 0..4294967295; unit s}, "Presents a tiime value that shall be used by all ECUs to time-stamp diagnsotic trouble codes (DTC) according to the requirements for Global DTC snapshot data."}, init-value=constant-reference=CarTiGlb_5}, required-interface=CarTiGlb_5
      VehModMngtGlbSafe1: nonqueued-receiver-com-spec{composite-network-representations=[{leaf-element=VehModMngtGlbSafe1.UsgModSts, network-representation={base-type=UsgModSts1_2, compu-method=UsgModSts1_1, "UsageMode Status"}}, {leaf-element=VehModMngtGlbSafe1.CarModSts1, network-representation={base-type=CarModSts1_2, compu-method=CarModSts1_1, "CarMode Status"}}, {leaf-element=VehModMngtGlbSafe1.CarModSubtypWdCarModSubtyp, network-representation={base-type=Nr5_2, compu {identical; unit Unitless}, "CarMode substate status"}}, {leaf-element=VehModMngtGlbSafe1.EgyLvlElecMai, network-representation={base-type=UInt4_2, compu {identical; unit Unitless}, "Main energy level in the vehicle."}}, {leaf-element=VehModMngtGlbSafe1.EgyLvlElecSubtyp, network-representation={base-type=UInt4_2, compu {identical; unit Unitless}, "Substate of the energy level in the vehicle."}}, {leaf-element=VehModMngtGlbSafe1.PwrLvlElecMai, network-representation={base-type=UInt4_2, compu {identical; unit Unitless}, "Main Power level in the vehicle."}}, {leaf-element=VehModMngtGlbSafe1.PwrLvlElecSubtyp, network-representation={base-type=UInt4_2, compu {identical; unit Unitless}, "Substate of the power level in the vehicle."}}, {leaf-element=VehModMngtGlbSafe1.FltEgyCnsWdSts, network-representation={base-type=FltEgyCns1_2, compu {0=FltEgyCns1_NoFlt, 1=FltEgyCns1_Flt; unit Unitless}, "High quiescent current detected by CEM via BMS."}}, {leaf-element=VehModMngtGlbSafe1.Chks, network-representation={base-type=UInt8_2, compu {identical; unit Unitless}, "Checksum"}}, {leaf-element=VehModMngtGlbSafe1.Cntr, network-representation={base-type=UInt4_2, compu {identical; unit Unitless}, "Counter"}}], data-element=VehModMngtGlbSafe1, init-value=constant-reference=VehModMngtGlbSafe1_7}, required-interface=VehModMngtGlbSafe1_7
      VehBattU: nonqueued-receiver-com-spec{composite-network-representations=[{leaf-element=VehBattU.SysU, network-representation={base-type=U1_2, compu {phys=raw*0.1 for raw 0..250; unit Volt}, "Vehicle System Voltage At 12V side"}}, {leaf-element=VehBattU.SysUQf, network-representation={base-type=GenQf1_2, compu-method=GenQf1_1, "Present vehicle voltage measured by CEM with QF"}}], data-element=VehBattU, init-value=constant-reference=VehBattU_8}, required-interface=VehBattU_8
      BkpOfDstTrvld: nonqueued-receiver-com-spec{data-element=BkpOfDstTrvld, network-representation={base-type=Len31_2, compu {phys=raw for raw 0..2000000; unit km}, "total traveled distance."}, init-value=constant-reference=BkpOfDstTrvld_7}, required-interface=BkpOfDstTrvld_7
      VehCfgPrm: nonqueued-receiver-com-spec{composite-network-representations=[{leaf-element=VehCfgPrm.BlkIDBytePosn1, network-representation={base-type=Nr2_3, compu {phys=raw for raw 0..255; unit Unitless}, "signal block counter."}}, {leaf-element=VehCfgPrm.CCPBytePosn2, network-representation={base-type=Nr2_3, compu {phys=raw for raw 0..255; unit Unitless}, "(BlockID-1)*7 + 1."}}, {leaf-element=VehCfgPrm.CCPBytePosn3, network-representation={base-type=Nr2_3, compu {phys=raw for raw 0..255; unit Unitless}, "(BlockID-1)*7 + 2."}}, {leaf-element=VehCfgPrm.CCPBytePosn4, network-representation={base-type=Nr2_3, compu {phys=raw for raw 0..255; unit Unitless}, "(BlockID-1)*7 + 3."}}, {leaf-element=VehCfgPrm.CCPBytePosn5, network-representation={base-type=Nr2_3, compu {phys=raw for raw 0..255; unit Unitless}, "(BlockID-1)*7 + 4."}}, {leaf-element=VehCfgPrm.CCPBytePosn6, network-representation={base-type=Nr2_3, compu {phys=raw for raw 0..255; unit Unitless}, "(BlockID-1)*7 + 5."}}, {leaf-element=VehCfgPrm.CCPBytePosn7, network-representation={base-type=Nr2_3, compu {phys=raw for raw 0..255; unit Unitless}, "(BlockID-1)*7 + 6."}}, {leaf-element=VehCfgPrm.CCPBytePosn8, network-representation={base-type=Nr2_3, compu {phys=raw for raw 0..255; unit Unitless}, "(BlockID-1)*7 + 7."}}], data-element=VehCfgPrm, init-value=constant-reference=VehCfgPrm_5}, required-interface=VehCfgPrm_5
      VehCfgPrmExt: nonqueued-receiver-com-spec{composite-network-representations=[{leaf-element=VehCfgPrmExt.BlkIDBytePosn1, network-representation={base-type=Nr2_3, compu {phys=raw for raw 0..255; unit Unitless}, "CarConfigExtended BlockID"}}, {leaf-element=VehCfgPrmExt.CCPBytePosn2, network-representation={base-type=Nr2_3, compu {phys=raw for raw 0..255; unit Unitless}, "CarConfigExtended BytePos2"}}, {leaf-element=VehCfgPrmExt.CCPBytePosn3, network-representation={base-type=Nr2_3, compu {phys=raw for raw 0..255; unit Unitless}, "CarConfigExtended BytePos3"}}, {leaf-element=VehCfgPrmExt.CCPBytePosn4, network-representation={base-type=Nr2_3, compu {phys=raw for raw 0..255; unit Unitless}, "CarConfigExtended BytePos4"}}, {leaf-element=VehCfgPrmExt.CCPBytePosn5, network-representation={base-type=Nr2_3, compu {phys=raw for raw 0..255; unit Unitless}, "CarConfigExtended BytePos5"}}, {leaf-element=VehCfgPrmExt.CCPBytePosn6, network-representation={base-type=Nr2_3, compu {phys=raw for raw 0..255; unit Unitless}, "CarConfigExtended BytePos6"}}, {leaf-element=VehCfgPrmExt.CCPBytePosn7, network-representation={base-type=Nr2_3, compu {phys=raw for raw 0..255; unit Unitless}, "CarConfigExtended BytePos7"}}, {leaf-element=VehCfgPrmExt.CCPBytePosn8, network-representation={base-type=Nr2_3, compu {phys=raw for raw 0..255; unit Unitless}, "CarConfigExtended BytePos8"}}], data-element=VehCfgPrmExt, init-value=constant-reference=VehCfgPrmExt_2}, required-interface=VehCfgPrmExt_2
      ImobEngMgrReq2: nonqueued-receiver-com-spec{composite-network-representations=[{leaf-element=ImobEngMgrReq2.ImobEngMgrCmdTar1, network-representation={base-type=ImobEngMgrReqCmd_2, compu-method=ImobEngMgrReqCmd_1, "Command from CEM to IEM with desired immo status and 7 bytes of response Command from CEM"}}, {leaf-element=ImobEngMgrReq2.ImobEngDataMgrReq0, network-representation={base-type=UInt8_2, compu {identical; unit Unitless}, "Command from CEM to IEM with desired immo status and 7 bytes of response Byte 0"}}, {leaf-element=ImobEngMgrReq2.ImobEngDataMgrReq1, network-representation={base-type=UInt8_2, compu {identical; unit Unitless}, "Command from CEM to IEM with desired immo status and 7 bytes of response Byte 1"}}, {leaf-element=ImobEngMgrReq2.ImobEngDataMgrReq2, network-representation={base-type=UInt8_2, compu {identical; unit Unitless}, "Command from CEM to IEM with desired immo status and 7 bytes of response Byte 2"}}, {leaf-element=ImobEngMgrReq2.ImobEngDataMgrReq3, network-representation={base-type=UInt8_2, compu {identical; unit Unitless}, "Command from CEM to IEM with desired immo status and 7 bytes of response Byte 3"}}, {leaf-element=ImobEngMgrReq2.ImobEngDataMgrReq4, network-representation={base-type=UInt8_2, compu {identical; unit Unitless}, "Command from CEM to IEM with desired immo status and 7 bytes of response Byte 4"}}, {leaf-element=ImobEngMgrReq2.ImobEngDataMgrReq5, network-representation={base-type=UInt8_2, compu {identical; unit Unitless}, "Command from CEM to IEM with desired immo status and 7 bytes of response Byte 5"}}, {leaf-element=ImobEngMgrReq2.ImobEngDataMgrReq6, network-representation={base-type=UInt8_2, compu {identical; unit Unitless}, "Command from CEM to IEM with desired immo status and 7 bytes of response Byte 6"}}], data-element=ImobEngMgrReq2, init-value=constant-reference=ImobEngMgrReq2_4}, required-interface=ImobEngMgrReq2_4
      EngSt1WdSts: nonqueued-receiver-com-spec{composite-network-representations=[{leaf-element=EngSt1WdSts.EngSt1WdSts, network-representation={base-type=EngSt1_2, compu-method=EngSt1_1, "Signaling the state of the powerpack"}}, {leaf-element=EngSt1WdSts.Chks, network-representation={base-type=UInt8_2, compu {identical; unit Unitless}, "checksum"}}, {leaf-element=EngSt1WdSts.Cntr, network-representation={base-type=UInt4_2, compu {identical; unit Unitless}, "counter"}}], data-element=EngSt1WdSts, init-value=constant-reference=EngSt1WdSts_4}, required-interface=EngSt1WdSts_4
      VehSpdLgt: nonqueued-receiver-com-spec{composite-network-representations=[{leaf-element=VehSpdLgt.VehSpdLgtA, network-representation={base-type=Spd1_2, compu {phys=raw*0.00391 for raw 0..31970; unit m/s}, "Vehicle speed longitudinal based on wheel speed sensors and longitudinal acceleration."}}, {leaf-element=VehSpdLgt.VehSpdLgtQf, network-representation={base-type=GenQf1_2, compu-method=GenQf1_1, "Quality factor for vehicle speed as measured by wheel speed sensors and longitudinal acceleration."}}, {leaf-element=VehSpdLgt.VehSpdLgtCntr, network-representation={base-type=UInt4_2, compu {identical; unit Unitless}, "Counter"}}, {leaf-element=VehSpdLgt.VehSpdLgtChks, network-representation={base-type=UInt8_2, compu {identical; unit Unitless}, "Checksum"}}], data-element=VehSpdLgt, uses-end-to-end-protection=true, init-value=constant-reference=VehSpdLgt_15}, required-interface=VehSpdLgt_15
      HvSysRlySts: nonqueued-receiver-com-spec{composite-network-representations=[{leaf-element=HvSysRlySts.HvSysRlySts, network-representation={base-type=HvActvnSts_2, compu-method=HvActvnSts_1, "Actual state of the main contactors."}}, {leaf-element=HvSysRlySts.Cntr, network-representation={base-type=UInt4_2, compu {identical; unit Unitless}, "Counter for E2E"}}, {leaf-element=HvSysRlySts.Chks, network-representation={base-type=UInt8_2, compu {identical; unit Unitless}, "Checksum for E2E"}}], data-element=HvSysRlySts, uses-end-to-end-protection=true, alive-timeout=0.35, init-value=constant-reference=HvSysRlySts_8}, required-interface=HvSysRlySts_8
      CooltFlowForDtElec: nonqueued-receiver-com-spec{data-element=CooltFlowForDtElec, network-representation={base-type=CooltFlow2_2, compu {phys=raw*0.1 for raw 0..511; unit L / min}, "Predicted coolant low for Electric Drivetrain (ED) coolant circuit."}, init-value=constant-reference=CooltFlowForDtElec_5}, required-interface=CooltFlowForDtElec_5
      CooltTSigForDtElec: nonqueued-receiver-com-spec{data-element=CooltTSigForDtElec, network-representation={base-type=CooltTHiResl_2, compu {phys=raw*0.1-40 for raw 0..1800; unit degC}, "Coolant temperature measured by sensors installed in emotor cooling citcuit."}, init-value=constant-reference=CooltTSigForDtElec_5}, required-interface=CooltTSigForDtElec_5
      WhlMotSysModReq: nonqueued-receiver-com-spec{data-element=WhlMotSysModReq, network-representation={base-type=WhlMotSysModStsTyp1_2, compu-method=WhlMotSysModStsTyp1_1, "Mode request for motor drive system connected to wheel shaft."}, alive-timeout=0.5, init-value=constant-reference=WhlMotSysModReq_2}, required-interface=WhlMotSysModReq_2
      WhlMotSysActvDampgModReq: nonqueued-receiver-com-spec{data-element=WhlMotSysActvDampgModReq, network-representation={base-type=WhlMotSysActvDampgModCodSts_2, compu-method=WhlMotSysActvDampgModCodSts_1, "ERAD active damping mod request."}, init-value=constant-reference=WhlMotSysActvDampgModReq_2}, required-interface=WhlMotSysActvDampgModReq_2
      WhlMotSysPwrLimMax: nonqueued-receiver-com-spec{data-element=WhlMotSysPwrLimMax, network-representation={base-type=PrpsnPwrLimMax_2, compu {phys=raw*0.5 for raw 0..1022; unit kW}, "Maximum electric motor powerlimit on DC side. Positive power means power flowing into inverter."}, init-value=constant-reference=WhlMotSysPwrLimMax_2}, required-interface=WhlMotSysPwrLimMax_2
      WhlMotSysPwrLimMin: nonqueued-receiver-com-spec{data-element=WhlMotSysPwrLimMin, network-representation={base-type=PrpsnPwrLimMin_2, compu {phys=raw*0.5-511 for raw 0..1022; unit kW}, "Minimum electric motor powerlimit on DC side. Positive power means power flowing into inverter."}, init-value=constant-reference=WhlMotSysPwrLimMin_2}, required-interface=WhlMotSysPwrLimMin_2
      PrpsnFbLimnIndcn: nonqueued-receiver-com-spec{data-element=PrpsnFbLimnIndcn, network-representation={base-type=UInt4_2, compu {identical; unit Unitless}, "Feedback signal that the present limitation has lead to a recofiguraton that has affected the driver."}, init-value=constant-reference=PrpsnFbLimnIndcn_2}, required-interface=PrpsnFbLimnIndcn_2
      DrvgCyc: nonqueued-receiver-com-spec{data-element=DrvgCyc, network-representation={base-type=OnOff1_2, compu {0=OnOff1_Off, 1=OnOff1_On; unit Unitless}, "Transition from 0 to 1 indicates a start of a new Driving Cycle."}, init-value=constant-reference=DrvgCyc_3}, required-interface=DrvgCyc_3
      RearHeatModEnad: nonqueued-receiver-com-spec{data-element=RearHeatModEnad, network-representation={base-type=FrntHeatModEnad_1, compu-method=FrntHeatModEnad_1, "Active heating enabling signal for rear motor"}, init-value=constant-reference=RearHeatModEnad_2}, required-interface=RearHeatModEnad_2
      RearHeatPwrAllwd: nonqueued-receiver-com-spec{data-element=RearHeatPwrAllwd, network-representation={base-type=IsgHeatPwr_1, compu {phys=raw*50 for raw 0..255; unit W}, "The allowed electrial energy for active heating of the rear motor"}, init-value=constant-reference=RearHeatPwrAllwd_1}, required-interface=RearHeatPwrAllwd_1
      PtTqAtAxleMaxReq: nonqueued-receiver-com-spec{composite-network-representations=[{leaf-element=PtTqAtAxleMaxReq.PtTqAtAxleFrntReq, network-representation={base-type=Tq2_2, compu {phys=raw for raw -20000..20000; unit NewtonMeter}, "Maximum allowed powertrain applied torque on the front axle."}}, {leaf-element=PtTqAtAxleMaxReq.PtTqAtAxleReReq, network-representation={base-type=Tq2_2, compu {phys=raw for raw -20000..20000; unit NewtonMeter}, "Maximum allowed powertrain applied torque on the rear axle."}}, {leaf-element=PtTqAtAxleMaxReq.Chks, network-representation={base-type=UInt8_2, compu {identical; unit Unitless}, "checksum"}}, {leaf-element=PtTqAtAxleMaxReq.Cntr, network-representation={base-type=UInt4_2, compu {identical; unit Unitless}, "counter"}}], data-element=PtTqAtAxleMaxReq, alive-timeout=0.5, init-value=constant-reference=PtTqAtAxleMaxReq_2}, required-interface=PtTqAtAxleMaxReq_2
      VehMtnSt: nonqueued-receiver-com-spec{composite-network-representations=[{leaf-element=VehMtnSt.VehMtnSt, network-representation={base-type=VehMtnSt2_2, compu-method=VehMtnSt2_1, "Vehicle motion state information based on wheel speed sensors. Provides information about vehicle stand still and vehicle rolling direction. Vehicle motion state"}}, {leaf-element=VehMtnSt.VehMtnStChks, network-representation={base-type=UInt8_2, compu {identical; unit Unitless}, "Vehicle motion state information based on wheel speed sensors. Provides information about vehicle stand still and vehicle rolling direction. Checksum for vehicle motion state"}}, {leaf-element=VehMtnSt.VehMtnStCntr, network-representation={base-type=UInt4_2, compu {identical; unit Unitless}, "Vehicle motion state information based on wheel speed sensors. Provides information about vehicle stand still and vehicle rolling direction. Counter for vehicle motion state"}}], data-element=VehMtnSt, uses-end-to-end-protection=true, init-value=constant-reference=VehMtnSt_10}, required-interface=VehMtnSt_10
      CrashStsSafe: nonqueued-receiver-com-spec{composite-network-representations=[{leaf-element=CrashStsSafe.Sts, network-representation={base-type=CrashSts2_2, compu {0=CrashSts2_NoCrash, 1=CrashSts2_Crash; unit Unitless}, "Information if a crash has been detected by SRS."}}, {leaf-element=CrashStsSafe.Chks, network-representation={base-type=UInt8_2, compu {identical; unit Unitless}, "Checksum for E2E"}}, {leaf-element=CrashStsSafe.Cntr, network-representation={base-type=UInt4_2, compu {identical; unit Unitless}, "Counter for E2E"}}], data-element=CrashStsSafe, uses-end-to-end-protection=true, alive-timeout=1.0, init-value=constant-reference=CrashStsSafe_2}, required-interface=CrashStsSafe_2
      WhlMotSysTqAllwd: nonqueued-receiver-com-spec{composite-network-representations=[{leaf-element=WhlMotSysTqAllwd.WhlMotSysTqAllwd, network-representation={base-type=UInt2_2, compu {identical; unit Unitless}, "Indication if ERAD is allowed to apply propulsive or regenerative torque on wheels. Bit 0: Propulsive torque allowed Bit 1: Regenerative torque allowed"}}, {leaf-element=WhlMotSysTqAllwd.Chks, network-representation={base-type=UInt8_2, compu {identical; unit Unitless}, "Checksum for WhlMotSysTqAllwd"}}, {leaf-element=WhlMotSysTqAllwd.Cntr, network-representation={base-type=UInt4_2, compu {identical; unit Unitless}, "Counter for WhlMotSysTqAllwd"}}], data-element=WhlMotSysTqAllwd, uses-end-to-end-protection=true, alive-timeout=0.5, init-value=constant-reference=WhlMotSysTqAllwd_7}, required-interface=WhlMotSysTqAllwd_7
      GearLvrIndcn: nonqueued-receiver-com-spec{data-element=GearLvrIndcn, network-representation={base-type=GearLvrIndcn2_2, compu-method=GearLvrIndcn2_1, "Gear lever indication (drivetrain position) to the driver. If drivetrain position is not possible to decide signal is set to undefined. Valid for automatic vehicles."}, init-value=constant-reference=GearLvrIndcn_6}, required-interface=GearLvrIndcn_6
      HvBattSoc: nonqueued-receiver-com-spec{data-element=HvBattSoc, network-representation={base-type=Perc7_2, compu {phys=raw*0.05 for raw 0..2000; unit %}, "Actual state of charge of the Hv Battery."}, init-value=constant-reference=HvBattSoc_2}, required-interface=HvBattSoc_2
      HvBattUDynMinLim: nonqueued-receiver-com-spec{data-element=HvBattUDynMinLim, network-representation={base-type=HvU1_2, compu {phys=raw*0.25 for raw 0..2044; unit Volt}, "The pack voltage low limit of the Hv Battery, dynamically based on cell voltage distribution. At pack voltages below this limit, there is risk for contactor openeing due to too low cell voltage"}, init-value=constant-reference=HvBattUDynMinLim_4}, required-interface=HvBattUDynMinLim_4
      HvBattUDynMaxLim: nonqueued-receiver-com-spec{data-element=HvBattUDynMaxLim, network-representation={base-type=HvU1_2, compu {phys=raw*0.25 for raw 0..2044; unit Volt}, "The pack voltage high limit of the Hv Battery, dynamically based on cell voltage distribution. At pack voltages above this limit, there is risk for contactor openeing due to too high cell voltage."}, init-value=constant-reference=HvBattUDynMaxLim_4}, required-interface=HvBattUDynMaxLim_4
      HvBattUDc: nonqueued-receiver-com-spec{data-element=HvBattUDc, network-representation={base-type=HvU1_2, compu {phys=raw*0.25 for raw 0..2044; unit Volt}, "Actual Hv Battery pack voltage (measuered before contactors, i.e. always giving pack voltage)."}, init-value=constant-reference=HvBattUDc_3}, required-interface=HvBattUDc_3
      WhlMotSysTqReq: nonqueued-receiver-com-spec{data-element=WhlMotSysTqReq, network-representation={base-type=HvTq1_2, compu {phys=raw*4-8188 for raw 0..4095; unit NewtonMeter}, "Requested electric motor torque referred to the wheel axle. The torque is positive in the forward rotation direction."}, alive-timeout=0.5, init-value=constant-reference=WhlMotSysTqReq_2}, required-interface=WhlMotSysTqReq_2
      SpdRotlForWhlsAtAxleRe: nonqueued-receiver-com-spec{data-element=SpdRotlForWhlsAtAxleRe, network-representation={base-type=N1_2, compu {phys=raw*0.5 for raw 0..32767; unit rpm}, "Average angular velocity of rear wheels."}, init-value=constant-reference=SpdRotlForWhlsAtAxleRe_7}, required-interface=SpdRotlForWhlsAtAxleRe_7
      PLockParkReq: nonqueued-receiver-com-spec{data-element=PLockParkReq, network-representation={base-type=PLockParkRequest_1, compu-method=PLockParkRequest_1, "Park request to P-Lock."}, init-value=constant-reference=PLockParkReq_1}, required-interface=PLockParkReq_1
      DCChrgnHndlSts: nonqueued-receiver-com-spec{data-element=DCChrgnHndlSts, network-representation={base-type=OnBdChrgrHndlSts_2, compu-method=OnBdChrgrHndlSts_1, "Fast charging gun connect state"}, init-value=constant-reference=DCChrgnHndlSts_5}, required-interface=DCChrgnHndlSts_5
      OnBdChrgrHndlSts1: nonqueued-receiver-com-spec{data-element=OnBdChrgrHndlSts1, network-representation={base-type=OnBdChrgrHndlSts1_2, compu-method=OnBdChrgrHndlSts1_2, "Status of the Onboard Charger connection to the grid."}, init-value=constant-reference=OnBdChrgrHndlSts1_8}, required-interface=OnBdChrgrHndlSts1_8
package /PortInterfaces
  64 x sender receiver interface:
    DmcStsRearToEsc_2
      data DmcStsRearToEsc: type=DmcStsToEsc_1
    ImobEngChk2_4
      data ImobEngChk2: type=ImobEngChk_2
    ImobEngSts2_4
      data ImobEngSts2: type=ImobSts_2
    IEMTestFr1_1
      data IEMTestFr1: type=DevDataTyp64_2
    IEMTestFr2_1
      data IEMTestFr2: type=DevDataTyp64_2
    IEMTestFr3_3
      data IEMTestFr3: type=DevDataTyp64_2
    WhlMotSysCoolgReq_4
      data WhlMotSysCoolgReq: type=HvCoolg1_2
    WhlMotSysInvrT_4
      data WhlMotSysInvrT: type=T3_2
    WhlMotSysMotT_3
      data WhlMotSysMotT: type=T3_2
    WhlMotSysCooltT_4
      data WhlMotSysCooltT: type=HvT1_3
    WhlMotSysHeatPwrMax_1
      data WhlMotSysHeatPwrMax: type=IsgHeatPwr_1
    WhlMotSysHeatFdBck_1
      data WhlMotSysHeatFdBck: type=WhlMotSysHeatFdBck_1
    WhlMotSysHeatPwrAct_1
      data WhlMotSysHeatPwrAct: type=IsgHeatPwr_1
    WhlMotSysModSts_5
      data WhlMotSysModSts: type=WhlMotSysModStsTyp2_2
    WhlMotSysLimnIndcn_3
      data WhlMotSysLimnIndcn: type=UInt16_2
    WhlMotClrRdyReq_4
      data WhlMotClrRdyReq: type=OnOff1_2
    WhlMotSysErrIndcnReq_4
      data WhlMotSysErrIndcnReq: type=OnOff1_2
    IemGeneric_12
      data IemGeneric: type=ElecDrvGen_4
    WhlMotSysIdc_5
      data WhlMotSysIdc: type=Ampr1_1
    WhlMotSysUdc_3
      data WhlMotSysUdc: type=HvU1_2
    WhlMotCooltFlowMinReq_2
      data WhlMotCooltFlowMinReq: type=CooltFlowForDtElec1_2
    WhlMotSysSpdAct_4
      data WhlMotSysSpdAct: type=IsgSpdWSgnTyp_2
    WhlMotSysTqAvl_4
      data WhlMotSysTqAvl: type=WhlMotSysTqAvl_2
    WhlMotSysTqEst_10
      data WhlMotSysTqEst: type=IsgTqActSafe2_4
    WhlMotSysSpdActSafe_1
      data WhlMotSysSpdActSafe: type=SpdSgnSafe_1
    PLockParkStsRe_1
      data PLockParkStsRe: type=ParkSts_1
    PLockFltIndcRe_1
      data PLockFltIndcRe: type=FltIndcn_1
    PLockFltLvlRe_1
      data PLockFltLvlRe: type=FltLvl_1
    WhlMotSysTqReq_2
      data WhlMotSysTqReq: type=HvTq1_2
    GearLvrIndcn_6
      data GearLvrIndcn: type=GearLvrIndcn2_2
    StcStsToDmc_3
      data StcStsToDmc: type=StcStsToDmc_1
    EscVariantToDmc_1
      data EscVariantToDmc: type=EscVariantToDmc_1
    CarTiGlb_5
      data CarTiGlb: type=CarTiGlb_2
    VehModMngtGlbSafe1_7
      data VehModMngtGlbSafe1: type=VehModMngtGlbSafe1_2
    VehBattU_8
      data VehBattU: type=SysU_4
    BkpOfDstTrvld_7
      data BkpOfDstTrvld: type=Len31_2
    VehCfgPrm_5
      data VehCfgPrm: type=VehCfgPrm_3
    VehCfgPrmExt_2
      data VehCfgPrmExt: type=VehCfgPrm_3
    ImobEngMgrReq2_4
      data ImobEngMgrReq2: type=ImobEngMgrReq_2
    EngSt1WdSts_4
      data EngSt1WdSts: type=EngSt1WdSts_1
    VehSpdLgt_15
      data VehSpdLgt: type=VehSpdLgtSafe1_3
    HvSysRlySts_8
      data HvSysRlySts: type=HvSysRlySts_1
    CooltFlowForDtElec_5
      data CooltFlowForDtElec: type=CooltFlow2_2
    CooltTSigForDtElec_5
      data CooltTSigForDtElec: type=CooltTHiResl_2
    WhlMotSysModReq_2
      data WhlMotSysModReq: type=WhlMotSysModStsTyp1_2
    WhlMotSysActvDampgModReq_2
      data WhlMotSysActvDampgModReq: type=WhlMotSysActvDampgModCodSts_2
    WhlMotSysPwrLimMax_2
      data WhlMotSysPwrLimMax: type=PrpsnPwrLimMax_2
    WhlMotSysPwrLimMin_2
      data WhlMotSysPwrLimMin: type=PrpsnPwrLimMin_2
    PrpsnFbLimnIndcn_2
      data PrpsnFbLimnIndcn: type=UInt4_2
    DrvgCyc_3
      data DrvgCyc: type=OnOff1_2
    RearHeatModEnad_2
      data RearHeatModEnad: type=FrntHeatModEnad_1
    RearHeatPwrAllwd_1
      data RearHeatPwrAllwd: type=IsgHeatPwr_1
    PtTqAtAxleMaxReq_2
      data PtTqAtAxleMaxReq: type=PtTqAtAxleReq_1
    VehMtnSt_10
      data VehMtnSt: type=VehMtnStSafe1_2
    CrashStsSafe_2
      data CrashStsSafe: type=CrashStsSafe_1
    WhlMotSysTqAllwd_7
      data WhlMotSysTqAllwd: type=WhlMotSysTqAllwd_3
    HvBattSoc_2
      data HvBattSoc: type=Perc7_2
    HvBattUDynMinLim_4
      data HvBattUDynMinLim: type=HvU1_2
    HvBattUDynMaxLim_4
      data HvBattUDynMaxLim: type=HvU1_2
    HvBattUDc_3
      data HvBattUDc: type=HvU1_2
    SpdRotlForWhlsAtAxleRe_7
      data SpdRotlForWhlsAtAxleRe: type=N1_2
    PLockParkReq_1
      data PLockParkReq: type=PLockParkRequest_1
    DCChrgnHndlSts_5
      data DCChrgnHndlSts: type=OnBdChrgrHndlSts_2
    OnBdChrgrHndlSts1_8
      data OnBdChrgrHndlSts1: type=OnBdChrgrHndlSts1_2
package /ApplicationDataTypes
  application record data type DmcStsToEsc_1: category=STRUCTURE
    5 x application record element, all with category=VALUE:
      DmcSts: type=DMC_1
      DmcActAppTarTq: type=Tq35_1
      Cntr: type=UInt4_2
      Chks: type=UInt8_2
      DmcSWInfo: type=UInt16_2
  5 x app type, all with category=VALUE:
    DMC_1: compu {0=DMC_Init, 1=DMC_On, 2=DMC_Off, 3=DMC_Fault; unit Unitless}, range raw 0..3
    Tq35_1: compu {phys=raw for raw -30000..30000; unit NewtonMeter}, range phys -30000..30000 NewtonMeter
    UInt4_2: compu {identical; unit Unitless}, range phys 0..15 Unitless
    UInt8_2: compu {identical; unit Unitless}, range phys 0..255 Unitless
    UInt16_2: compu {identical; unit Unitless}, range phys 0..65535 Unitless
  application record data type ImobEngChk_2: category=STRUCTURE
    8 x application record element, all with category=VALUE:
      ImobEngChkSts: type=AvlSts2_2
      ImobEngDataChk{0..6}: type=UInt8_2
  app type AvlSts2_2: category=VALUE, compu {0=AvlSts2_NotAvl, 1=AvlSts2_Avl; unit Unitless}, range raw 0..1
  app type ImobSts_2: category=VALUE, compu-method=ImobSts_1, range raw 0..3
  application record data type DevDataTyp64_2: category=STRUCTURE
    8 x application record element, all with category=VALUE, type=UInt8_2:
      Byte{0..7}
  7 x app type, all with category=VALUE:
    HvCoolg1_2: compu-method=HvCoolg1_1, range raw 0..4
    T3_2: compu {phys=raw-50 for raw 0..250; unit degC}, range phys -50..200 degC
    HvT1_3: compu {phys=raw-40 for raw 0..255; unit degC}, range phys -40..215 degC
    IsgHeatPwr_1: compu {phys=raw*50 for raw 0..255; unit W}, range phys 0..12750 W
    WhlMotSysHeatFdBck_1: compu-method=WhlMotSysHeatFdBck_1, range raw 0..3
    WhlMotSysModStsTyp2_2: compu-method=WhlMotSysModStsTyp2_2, range raw 0..8
    OnOff1_2: compu {0=OnOff1_Off, 1=OnOff1_On; unit Unitless}, range raw 0..1
  application record data type ElecDrvGen_4: category=STRUCTURE
    16 x application record element, all with category=VALUE:
      EMQnty: type=UInt4_2
      EMSeqNr: type=UInt4_2
      DTCSts: type=UInt8_2
      DTCLow: type=UInt8_2
      DTCMid: type=UInt8_2
      DTCHig: type=UInt8_2
      TypeInfo: type=UInt4_2
      MotTAlrmSt: type=AlrmSt_2
      InvrtTAlrmSt: type=AlrmSt_2
      FltAlrmSt: type=AlrmSt_2
      SpdAlrmSt: type=AlrmSt_2
      IacAlrmSt: type=AlrmSt_2
      UDcAlrmSt: type=AlrmSt_2
      RslAlrmSt: type=AlrmSt_2
      ADAlrmSt: type=AlrmSt_2
      ModStatusRms: type=ModStatusRms_2
  6 x app type, all with category=VALUE:
    AlrmSt_2: compu {0=AlrmSt_Disarmd, 1=AlrmSt_Armd, 2=AlrmSt_Actv; unit Unitless}, range raw 0..2
    ModStatusRms_2: compu-method=ModStatusRms_2, range raw 0..15
    Ampr1_1: compu {phys=raw*0.1-818.8 for raw 0..16380; unit A}, range phys -818.8..819.2 A
    HvU1_2: compu {phys=raw*0.25 for raw 0..2044; unit Volt}, range phys 0..511 Volt
    CooltFlowForDtElec1_2: compu {phys=raw*0.01 for raw 0..1023; unit L / min}, range phys 0..10.23 L / min
    IsgSpdWSgnTyp_2: compu {phys=raw for raw -16384..16383; unit rpm}, range phys -16384..16383 rpm
  application record data type WhlMotSysTqAvl_2: category=STRUCTURE
    application record element TqAvlMax: category=VALUE, type=HvTq1_2
    application record element TqAvlMin: category=VALUE, type=HvTq1_2
  app type HvTq1_2: category=VALUE, compu {phys=raw*4-8188 for raw 0..4095; unit NewtonMeter}, range phys -8188..8192 NewtonMeter
  application record data type IsgTqActSafe2_4: category=STRUCTURE
    4 x application record element, all with category=VALUE:
      Cntr: type=UInt4_2
      Chks: type=UInt8_2
      QualityFactor: type=QualityFactor_2
      IsgTqAct: type=Tq34_1
  app type QualityFactor_2: category=VALUE, compu-method=QualityFactor_1, range raw 0..3
  app type Tq34_1: category=VALUE, compu {phys=raw-8188 for raw 0..16380; unit NewtonMeter}, range phys -8188..8192 NewtonMeter
  application record data type SpdSgnSafe_1: category=STRUCTURE
    4 x application record element, all with category=VALUE:
      IsgSpdWSgnTyp: type=IsgSpdWSgnTyp_2
      Chks: type=UInt8_2
      Cntr: type=UInt4_2
      Qf: type=GenQf1_2
  5 x app type, all with category=VALUE:
    GenQf1_2: compu-method=GenQf1_1, range raw 0..3
    ParkSts_1: compu-method=ParkSts_1, range raw 0..8
    FltIndcn_1: compu-method=FltIndcn_1, range raw 0..4
    FltLvl_1: compu {0=FltLvl_NoFlt, 1=FltLvl_FltLvl1, 2=FltLvl_FltLvl2; unit Unitless}, range raw 0..2
    GearLvrIndcn2_2: compu-method=GearLvrIndcn2_1, range raw 0..7
  application record data type StcStsToDmc_1: category=STRUCTURE
    6 x application record element, all with category=VALUE:
      StcStsToDmcFrnt: type=ModeDMC_1
      StcStsToDmcRear: type=ModeDMC_1
      EngRotTarSpdDMCFrnt: type=UInt16_2
      EngRotTarSpdDMCRear: type=UInt16_2
      Chks: type=UInt8_2
      Cntr: type=UInt4_2
  app type ModeDMC_1: category=VALUE, compu {0=ModeDMC_Off, 1=ModeDMC_Rpm, 2=ModeDMC_Trq; unit Unitless}, range raw 0..2
  application record data type EscVariantToDmc_1: category=STRUCTURE
    application record element EscVariantToDmc: category=VALUE, type=UInt8_2
    application record element Chks: category=VALUE, type=UInt8_2
    application record element Cntr: category=VALUE, type=UInt4_2
  app type CarTiGlb_2: category=VALUE, compu {phys=raw*0.1 for raw 0..4294967295; unit s}, range phys 0..429496729.4 s
  application record data type VehModMngtGlbSafe1_2: category=STRUCTURE
    10 x application record element, all with category=VALUE:
      UsgModSts: type=UsgModSts1_2
      CarModSts1: type=CarModSts1_2
      CarModSubtypWdCarModSubtyp: type=Nr5_2
      EgyLvlElecMai: type=UInt4_2
      EgyLvlElecSubtyp: type=UInt4_2
      PwrLvlElecMai: type=UInt4_2
      PwrLvlElecSubtyp: type=UInt4_2
      FltEgyCnsWdSts: type=FltEgyCns1_2
      Chks: type=UInt8_2
      Cntr: type=UInt4_2
  4 x app type, all with category=VALUE:
    UsgModSts1_2: compu-method=UsgModSts1_1, range raw 0..13
    CarModSts1_2: compu-method=CarModSts1_1, range raw 0..5
    Nr5_2: compu {identical; unit Unitless}, range phys 0..7 Unitless
    FltEgyCns1_2: compu {0=FltEgyCns1_NoFlt, 1=FltEgyCns1_Flt; unit Unitless}, range raw 0..1
  application record data type SysU_4: category=STRUCTURE
    application record element SysU: category=VALUE, type=U1_2
    application record element SysUQf: category=VALUE, type=GenQf1_2
  app type U1_2: category=VALUE, compu {phys=raw*0.1 for raw 0..250; unit Volt}, range phys 0..25 Volt
  app type Len31_2: category=VALUE, compu {phys=raw for raw 0..2000000; unit km}, range phys 0..2000000 km
  application record data type VehCfgPrm_3: category=STRUCTURE
    8 x application record element, all with category=VALUE, type=Nr2_3:
      BlkIDBytePosn1
      CCPBytePosn{2..8}
  app type Nr2_3: category=VALUE, compu {phys=raw for raw 0..255; unit Unitless}, range phys 0..255 Unitless
  application record data type ImobEngMgrReq_2: category=STRUCTURE
    8 x application record element, all with category=VALUE:
      ImobEngMgrCmdTar1: type=ImobEngMgrReqCmd_2
      ImobEngDataMgrReq{0..6}: type=UInt8_2
  app type ImobEngMgrReqCmd_2: category=VALUE, compu-method=ImobEngMgrReqCmd_1, range raw 0..3
  application record data type EngSt1WdSts_1: category=STRUCTURE
    application record element EngSt1WdSts: category=VALUE, type=EngSt1_2
    application record element Chks: category=VALUE, type=UInt8_2
    application record element Cntr: category=VALUE, type=UInt4_2
  app type EngSt1_2: category=VALUE, compu-method=EngSt1_1, range raw 0..9
  application record data type VehSpdLgtSafe1_3: category=STRUCTURE
    4 x application record element, all with category=VALUE:
      VehSpdLgtA: type=Spd1_2
      VehSpdLgtQf: type=GenQf1_2
      VehSpdLgtCntr: type=UInt4_2
      VehSpdLgtChks: type=UInt8_2
  app type Spd1_2: category=VALUE, compu {phys=raw*0.00391 for raw 0..31970; unit m/s}, range phys 0..125 m/s
  application record data type HvSysRlySts_1: category=STRUCTURE
    application record element HvSysRlySts: category=VALUE, type=HvActvnSts_2
    application record element Cntr: category=VALUE, type=UInt4_2
    application record element Chks: category=VALUE, type=UInt8_2
  8 x app type, all with category=VALUE:
    HvActvnSts_2: compu-method=HvActvnSts_1, range raw 0..3
    CooltFlow2_2: compu {phys=raw*0.1 for raw 0..511; unit L / min}, range phys 0..51.1 L / min
    CooltTHiResl_2: compu {phys=raw*0.1-40 for raw 0..1800; unit degC}, range phys -40..140 degC
    WhlMotSysModStsTyp1_2: compu-method=WhlMotSysModStsTyp1_1, range raw 0..7
    WhlMotSysActvDampgModCodSts_2: compu-method=WhlMotSysActvDampgModCodSts_1, range raw 0..3
    PrpsnPwrLimMax_2: compu {phys=raw*0.5 for raw 0..1022; unit kW}, range phys 0..511 kW
    PrpsnPwrLimMin_2: compu {phys=raw*0.5-511 for raw 0..1022; unit kW}, range phys -511..0 kW
    FrntHeatModEnad_1: compu-method=FrntHeatModEnad_1, range raw 0..3
  application record data type PtTqAtAxleReq_1: category=STRUCTURE
    4 x application record element, all with category=VALUE:
      PtTqAtAxleFrntReq: type=Tq2_2
      PtTqAtAxleReReq: type=Tq2_2
      Chks: type=UInt8_2
      Cntr: type=UInt4_2
  app type Tq2_2: category=VALUE, compu {phys=raw for raw -20000..20000; unit NewtonMeter}, range phys -20000..20000 NewtonMeter
  application record data type VehMtnStSafe1_2: category=STRUCTURE
    application record element VehMtnSt: category=VALUE, type=VehMtnSt2_2
    application record element VehMtnStChks: category=VALUE, type=UInt8_2
    application record element VehMtnStCntr: category=VALUE, type=UInt4_2
  app type VehMtnSt2_2: category=VALUE, compu-method=VehMtnSt2_1, range raw 0..7
  application record data type CrashStsSafe_1: category=STRUCTURE
    application record element Sts: category=VALUE, type=CrashSts2_2
    application record element Chks: category=VALUE, type=UInt8_2
    application record element Cntr: category=VALUE, type=UInt4_2
  app type CrashSts2_2: category=VALUE, compu {0=CrashSts2_NoCrash, 1=CrashSts2_Crash; unit Unitless}, range raw 0..1
  application record data type WhlMotSysTqAllwd_3: category=STRUCTURE
    application record element WhlMotSysTqAllwd: category=VALUE, type=UInt2_2
    application record element Chks: category=VALUE, type=UInt8_2
    application record element Cntr: category=VALUE, type=UInt4_2
  6 x app type, all with category=VALUE:
    UInt2_2: compu {identical; unit Unitless}, range phys 0..3 Unitless
    Perc7_2: compu {phys=raw*0.05 for raw 0..2000; unit %}, range phys 0..100 %
    N1_2: compu {phys=raw*0.5 for raw 0..32767; unit rpm}, range phys 0..16383.5 rpm
    PLockParkRequest_1: compu-method=PLockParkRequest_1, range raw 0..3
    OnBdChrgrHndlSts_2: compu-method=OnBdChrgrHndlSts_1, range raw 0..5
    OnBdChrgrHndlSts1_2: compu-method=OnBdChrgrHndlSts1_2, range raw 0..13
package /CompuMethods
  compu method ImobSts_1: 0=ImobSts_ImobUndefd, 1=ImobSts_ImobImobn, 2=ImobSts_ImobMtn, 3=ImobSts_ImobNoMtn; unit Unitless
  compu method HvCoolg1_1: 0=HvCoolg1_NoRequestForMoreCoolantPower, 1=HvCoolg1_IncreaseLevel1ForMoreCoolantPower, 2=HvCoolg1_IncreaseLevel2ForMoreCoolantPower, 3=HvCoolg1_MaxCoolingPower, 4=HvCoolg1_NotDefined; unit Unitless
  compu method WhlMotSysHeatFdBck_1: 0=WhlMotSysHeatFdBck_On, 1=WhlMotSysHeatFdBck_Off, 2=WhlMotSysHeatFdBck_Inhibt, 3=WhlMotSysHeatFdBck_Reserved; unit Unitless
  compu method WhlMotSysModStsTyp2_2: 0=WhlMotSysModStsTyp2_Inin, 1=WhlMotSysModStsTyp2_Stb, 2=WhlMotSysModStsTyp2_TqCtrl, 3=WhlMotSysModStsTyp2_SpdCtrlIdle, 4=WhlMotSysModStsTyp2_CluOper, 5=WhlMotSysModStsTyp2_PreChrg, 6=WhlMotSysModStsTyp2_PwrDwn, 7=WhlMotSysModStsTyp2_Flt, 8=WhlMotSysModStsTyp2_TcsCtrl; unit Unitless
  compu method ModStatusRms_2: 0=ModStatusRms_Invalid, 1=PModStatusRms_wrCns, 2=ModStatusRms_PwrGen, 3=ModStatusRms_OffSts, 4=ModStatusRms_RdySts, 5=ModStatusRms_Abnormal, 6..15=ModStatusRms_Invalid1..ModStatusRms_Invalid10; unit Unitless
  compu method QualityFactor_1: 0=QualityFactor_QfUndefd, 1=QualityFactor_QfInProgs, 2=QualityFactor_QfNotSpc, 3=QualityFactor_QfSnsrDataOk; unit Unitless
  compu method GenQf1_1: 0=GenQf1_UndefindDataAccur, 1=GenQf1_TmpUndefdData, 2=GenQf1_DataAccurNotWithinSpcn, 3=GenQf1_AccurData; unit Unitless
  compu method ParkSts_1: 0=ParkSts_Init, 1=ParkSts_Parked, 2=ParkSts_Parking, 3=ParkSts_StuckInParked, 4=ParkSts_StuckInUnparked, 5=ParkSts_Unparking, 6=ParkSts_Unparked, 7=ParkSts_Unknown, 8=ParkSts_Off; unit Unitless
  compu method FltIndcn_1: 0=FltIndcn_NoFlt, 1=FltIndcn_ComFlt, 2=FltIndcn_ActrFlt, 3=FltIndcn_SnsrFlt, 4=FltIndcn_RdmFlt; unit Unitless
  compu method GearLvrIndcn2_1: 0=GearLvrIndcn2_ParkIndcn, 1=GearLvrIndcn2_RvsIndcn, 2=GearLvrIndcn2_NeutIndcn, 3=GearLvrIndcn2_DrvIndcn, 4=GearLvrIndcn2_ManModeIndcn, 5=GearLvrIndcn2_Resd1, 6=GearLvrIndcn2_Resd2, 7=GearLvrIndcn2_Undefd; unit Unitless
  compu method UsgModSts1_1: 0=UsgModSts1_UsgModAbdnd, 1=UsgModSts1_UsgModInActv, 2=UsgModSts1_UsgModCnvinc, 11=UsgModSts1_UsgModActv, 13=UsgModSts1_UsgModDrvg; unit Unitless
  compu method CarModSts1_1: 0=CarModSts1_CarModNorm, 1=CarModSts1_CarModTrnsp, 2=CarModSts1_CarModFcy, 3=CarModSts1_CarModCrash, 5=CarModSts1_CarModDyno; unit Unitless
  compu method ImobEngMgrReqCmd_1: 0=ImobEngMgrReqCmd_ImobEngCmdTarIdle, 1=ImobEngMgrReqCmd_ImobEngMtnStrtReqCmd, 2=ImobEngMgrReqCmd_ImobEngNoMtnStrtReqCmd, 3=ImobEngMgrReqCmd_ImobEngTurnOffCmd; unit Unitless
  compu method EngSt1_1: 0=EngSt1_Ini, 1=EngSt1_Awake, 2=EngSt1_Rdy, 3=EngSt1_PreStrtg, 4=EngSt1_StrtgInProgs, 5=EngSt1_RunngRunng, 6=EngSt1_RunngStb, 7=EngSt1_RunngStrtgInProgs, 8=EngSt1_RunngRemStrtd, 9=EngSt1_AftRun; unit Unitless
  compu method HvActvnSts_1: 0=HvActvnSts_Open, 1=HvActvnSts_Clsd, 2=HvActvnSts_KeepSt, 3=HvActvnSts_OpenAndReqActvDcha; unit Unitless
  compu method WhlMotSysModStsTyp1_1: 0=WhlMotSysModStsTyp1_Inin, 1=WhlMotSysModStsTyp1_Stb, 2=WhlMotSysModStsTyp1_TqCtrl, 3=WhlMotSysModStsTyp1_SpdCtrlIdle, 4=WhlMotSysModStsTyp1_CluOper, 5=WhlMotSysModStsTyp1_PreChrg, 6=WhlMotSysModStsTyp1_PwrDwn, 7=WhlMotSysModStsTyp1_Flt; unit Unitless
  compu method WhlMotSysActvDampgModCodSts_1: 0=WhlMotSysActvDampgModCodSts_NoDampg, 1=WhlMotSysActvDampgModCodSts_LoDampg, 2=WhlMotSysActvDampgModCodSts_MedDampg, 3=WhlMotSysActvDampgModCodSts_HiDampg; unit Unitless
  compu method FrntHeatModEnad_1: 0=FrntHeatModEnad_Heatg, 1=FrntHeatModEnad_PwrLoss, 2=FrntHeatModEnad_Off, 3=FrntHeatModEnad_Reserved; unit Unitless
  compu method VehMtnSt2_1: 0=VehMtnSt2_Ukwn, 1=VehMtnSt2_StandStillVal1, 2=VehMtnSt2_StandStillVal2, 3=VehMtnSt2_StandStillVal3, 4=VehMtnSt2_RollgFwdVal1, 5=VehMtnSt2_RollgFwdVal2, 6=VehMtnSt2_RollgBackwVal1, 7=VehMtnSt2_RollgBackwVal2; unit Unitless
  compu method PLockParkRequest_1: 0=PLockParkRequest_NoReq, 1=PLockParkRequest_ReqApply, 2=PLockParkRequest_ReqRels, 3=PLockParkRequest_Reserved; unit Unitless
  compu method OnBdChrgrHndlSts_1: 0=OnBdChrgrHndlSts_Disconnected, 1=OnBdChrgrHndlSts_ConnectedWithoutPower, 2=OnBdChrgrHndlSts_PowerAvailableButNotActivated, 3=OnBdChrgrHndlSts_ConnectedWithPower, 4=OnBdChrgrHndlSts_Init, 5=OnBdChrgrHndlSts_Fault; unit Unitless
  compu method OnBdChrgrHndlSts1_2: 0=OnBdChrgrHndlSts1_Disconnected, 1=OnBdChrgrHndlSts1_ConnectedWithoutPower, 2=OnBdChrgrHndlSts1_PowerAvailableButNotActivated, 3=OnBdChrgrHndlSts1_ConnectedWithPower, 4=OnBdChrgrHndlSts1_DischargeConnectwithoutpowerincar, 5=OnBdChrgrHndlSts1_DischargeConnectwithoutpoweroutcar, 6=OnBdChrgrHndlSts1_DischargeConnectwithpowerincar, 7=OnBdChrgrHndlSts1_DischargeConnectwithpoweroutcar, 8=OnBdChrgrHndlSts1_Init, 9=OnBdChrgrHndlSts1_Fault, 10=OnBdChrgrHndlSts1_NotCompleteConnnected, 11=OnBdChrgrHndlSts1_Reserved0, 12=OnBdChrgrHndlSts1_Reserved1, 13=OnBdChrgrHndlSts1_Reserved2; unit Unitless
package /Units
  13 x unit:
    NoUnit_1: display-name=Unitless
    Nm_1: display-name=NewtonMeter
    DegCgrd_1: display-name=degC
    Watt_1: display-name=W
    Ampr_1: display-name=A
    Volt_1: display-name=Volt
    LPerMins_1: display-name=L / min
    Rpm_1: display-name=rpm
    Sec_1: display-name=s
    km_1: display-name=km
    MtrPerSec_1: display-name=m/s
    KiloWatt_1: display-name=kW
    Perc_1: display-name=%
package /ConstantSpecifications
  64 x constant specification:
    DmcStsRearToEsc_2: value-spec=fields=[0 Unitless, 0 NewtonMeter, 0 Unitless, 0 Unitless, 0 Unitless]
    ImobEngChk2_4: value-spec=fields=[0 Unitless, 0 Unitless, 0 Unitless, 0 Unitless, 0 Unitless, 0 Unitless, 0 Unitless, 0 Unitless]
    ImobEngSts2_4: value-spec=0 Unitless
    IEMTestFr1_1: value-spec=fields=[0 Unitless, 0 Unitless, 0 Unitless, 0 Unitless, 0 Unitless, 0 Unitless, 0 Unitless, 0 Unitless]
    IEMTestFr2_1: value-spec=fields=[0 Unitless, 0 Unitless, 0 Unitless, 0 Unitless, 0 Unitless, 0 Unitless, 0 Unitless, 0 Unitless]
    IEMTestFr3_3: value-spec=fields=[0 Unitless, 0 Unitless, 0 Unitless, 0 Unitless, 0 Unitless, 0 Unitless, 0 Unitless, 0 Unitless]
    WhlMotSysCoolgReq_4: value-spec=0 Unitless
    WhlMotSysInvrT_4: value-spec=0 degC
    WhlMotSysMotT_3: value-spec=0 degC
    WhlMotSysCooltT_4: value-spec=0 degC
    WhlMotSysHeatPwrMax_1: value-spec=0 W
    WhlMotSysHeatFdBck_1: value-spec=1 Unitless
    WhlMotSysHeatPwrAct_1: value-spec=0 W
    WhlMotSysModSts_5: value-spec=0 Unitless
    WhlMotSysLimnIndcn_3: value-spec=0 Unitless
    WhlMotClrRdyReq_4: value-spec=0 Unitless
    WhlMotSysErrIndcnReq_4: value-spec=0 Unitless
    IemGeneric_12: value-spec=fields=[0 Unitless, 0 Unitless, 0 Unitless, 0 Unitless, 0 Unitless, 0 Unitless, 0 Unitless, 0 Unitless, 0 Unitless, 0 Unitless, 0 Unitless, 0 Unitless, 0 Unitless, 0 Unitless, 0 Unitless, 3 Unitless]
    WhlMotSysIdc_5: value-spec=0 A
    WhlMotSysUdc_3: value-spec=0 Volt
    WhlMotCooltFlowMinReq_2: value-spec=0 L / min
    WhlMotSysSpdAct_4: value-spec=0 rpm
    WhlMotSysTqAvl_4: value-spec=fields=[0 NewtonMeter, 0 NewtonMeter]
    WhlMotSysTqEst_10: value-spec=fields=[0 Unitless, 0 Unitless, 1 Unitless, 0 NewtonMeter]
    WhlMotSysSpdActSafe_1: value-spec=fields=[0 rpm, 0 Unitless, 0 Unitless, 1 Unitless]
    PLockParkStsRe_1: value-spec=7 Unitless
    PLockFltIndcRe_1: value-spec=0 Unitless
    PLockFltLvlRe_1: value-spec=0 Unitless
    WhlMotSysTqReq_2: value-spec=0 NewtonMeter
    GearLvrIndcn_6: value-spec=7 Unitless
    StcStsToDmc_3: value-spec=fields=[0 Unitless, 0 Unitless, 0 Unitless, 0 Unitless, 0 Unitless, 0 Unitless]
    EscVariantToDmc_1: value-spec=fields=[0 Unitless, 0 Unitless, 0 Unitless]
    CarTiGlb_5: value-spec=0 s
    VehModMngtGlbSafe1_7: value-spec=fields=[1 Unitless, 0 Unitless, 0 Unitless, 0 Unitless, 0 Unitless, 0 Unitless, 0 Unitless, 0 Unitless, 0 Unitless, 0 Unitless]
    VehBattU_8: value-spec=fields=[0 Volt, 1 Unitless]
    BkpOfDstTrvld_7: value-spec=0 km
    VehCfgPrm_5: value-spec=fields=[0 Unitless, 0 Unitless, 0 Unitless, 0 Unitless, 0 Unitless, 0 Unitless, 0 Unitless, 0 Unitless]
    VehCfgPrmExt_2: value-spec=fields=[0 Unitless, 0 Unitless, 0 Unitless, 0 Unitless, 0 Unitless, 0 Unitless, 0 Unitless, 0 Unitless]
    ImobEngMgrReq2_4: value-spec=fields=[0 Unitless, 0 Unitless, 0 Unitless, 0 Unitless, 0 Unitless, 0 Unitless, 0 Unitless, 0 Unitless]
    EngSt1WdSts_4: value-spec=fields=[0 Unitless, 0 Unitless, 0 Unitless]
    VehSpdLgt_15: value-spec=fields=[0 m/s, 1 Unitless, 0 Unitless, 0 Unitless]
    HvSysRlySts_8: value-spec=fields=[2 Unitless, 0 Unitless, 0 Unitless]
    CooltFlowForDtElec_5: value-spec=0 L / min
    CooltTSigForDtElec_5: value-spec=0 degC
    WhlMotSysModReq_2: value-spec=0 Unitless
    WhlMotSysActvDampgModReq_2: value-spec=0 Unitless
    WhlMotSysPwrLimMax_2: value-spec=0 kW
    WhlMotSysPwrLimMin_2: value-spec=0 kW
    PrpsnFbLimnIndcn_2: value-spec=0 Unitless
    DrvgCyc_3: value-spec=0 Unitless
    RearHeatModEnad_2: value-spec=2 Unitless
    RearHeatPwrAllwd_1: value-spec=0 W
    PtTqAtAxleMaxReq_2: value-spec=fields=[20000 NewtonMeter, 20000 NewtonMeter, 0 Unitless, 0 Unitless]
    VehMtnSt_10: value-spec=fields=[0 Unitless, 0 Unitless, 0 Unitless]
    CrashStsSafe_2: value-spec=fields=[0 Unitless, 255 Unitless, 0 Unitless]
    WhlMotSysTqAllwd_7: value-spec=fields=[0 Unitless, 0 Unitless, 0 Unitless]
    HvBattSoc_2: value-spec=0 %
    HvBattUDynMinLim_4: value-spec=0 Volt
    HvBattUDynMaxLim_4: value-spec=0 Volt
    HvBattUDc_3: value-spec=0 Volt
    SpdRotlForWhlsAtAxleRe_7: value-spec=0 rpm
    PLockParkReq_1: value-spec=0 Unitless
    DCChrgnHndlSts_5: value-spec=0 Unitless
    OnBdChrgrHndlSts1_8: value-spec=8 Unitless
package /BaseTypes
  57 x base type, all with category=FIXED_LENGTH:
    DMC_1: base-type-size=4, base-type-encoding=NONE
    Tq35_1: base-type-size=16, base-type-encoding=2C
    UInt4_2: base-type-size=4, base-type-encoding=NONE
    UInt8_2: base-type-size=8, base-type-encoding=NONE
    UInt16_2: base-type-size=16, base-type-encoding=NONE
    AvlSts2_2: base-type-size=1, base-type-encoding=NONE
    ImobSts_2: base-type-size=2, base-type-encoding=NONE
    HvCoolg1_2: base-type-size=3, base-type-encoding=NONE
    T3_2: base-type-size=8, base-type-encoding=NONE
    HvT1_3: base-type-size=8, base-type-encoding=NONE
    IsgHeatPwr_1: base-type-size=8, base-type-encoding=NONE
    WhlMotSysHeatFdBck_1: base-type-size=2, base-type-encoding=NONE
    WhlMotSysModStsTyp2_2: base-type-size=4, base-type-encoding=NONE
    OnOff1_2: base-type-size=1, base-type-encoding=NONE
    AlrmSt_2: base-type-size=2, base-type-encoding=NONE
    ModStatusRms_2: base-type-size=4, base-type-encoding=NONE
    Ampr1_1: base-type-size=14, base-type-encoding=NONE
    HvU1_2: base-type-size=11, base-type-encoding=NONE
    CooltFlowForDtElec1_2: base-type-size=10, base-type-encoding=NONE
    IsgSpdWSgnTyp_2: base-type-size=15, base-type-encoding=2C
    HvTq1_2: base-type-size=12, base-type-encoding=NONE
    QualityFactor_2: base-type-size=2, base-type-encoding=NONE
    Tq34_1: base-type-size=14, base-type-encoding=NONE
    GenQf1_2: base-type-size=2, base-type-encoding=NONE
    ParkSts_1: base-type-size=4, base-type-encoding=NONE
    FltIndcn_1: base-type-size=3, base-type-encoding=NONE
    FltLvl_1: base-type-size=2, base-type-encoding=NONE
    GearLvrIndcn2_2: base-type-size=3, base-type-encoding=NONE
    ModeDMC_1: base-type-size=8, base-type-encoding=NONE
    CarTiGlb_2: base-type-size=32, base-type-encoding=NONE
    UsgModSts1_2: base-type-size=4, base-type-encoding=NONE
    CarModSts1_2: base-type-size=3, base-type-encoding=NONE
    Nr5_2: base-type-size=3, base-type-encoding=NONE
    FltEgyCns1_2: base-type-size=1, base-type-encoding=NONE
    U1_2: base-type-size=8, base-type-encoding=NONE
    Len31_2: base-type-size=21, base-type-encoding=NONE
    Nr2_3: base-type-size=8, base-type-encoding=NONE
    ImobEngMgrReqCmd_2: base-type-size=2, base-type-encoding=NONE
    EngSt1_2: base-type-size=4, base-type-encoding=NONE
    Spd1_2: base-type-size=15, base-type-encoding=NONE
    HvActvnSts_2: base-type-size=2, base-type-encoding=NONE
    CooltFlow2_2: base-type-size=9, base-type-encoding=NONE
    CooltTHiResl_2: base-type-size=11, base-type-encoding=NONE
    WhlMotSysModStsTyp1_2: base-type-size=3, base-type-encoding=NONE
    WhlMotSysActvDampgModCodSts_2: base-type-size=2, base-type-encoding=NONE
    PrpsnPwrLimMax_2: base-type-size=10, base-type-encoding=NONE
    PrpsnPwrLimMin_2: base-type-size=10, base-type-encoding=NONE
    FrntHeatModEnad_1: base-type-size=2, base-type-encoding=NONE
    Tq2_2: base-type-size=16, base-type-encoding=2C
    VehMtnSt2_2: base-type-size=3, base-type-encoding=NONE
    CrashSts2_2: base-type-size=1, base-type-encoding=NONE
    UInt2_2: base-type-size=2, base-type-encoding=NONE
    Perc7_2: base-type-size=11, base-type-encoding=NONE
    N1_2: base-type-size=15, base-type-encoding=NONE
    PLockParkRequest_1: base-type-size=2, base-type-encoding=NONE
    OnBdChrgrHndlSts_2: base-type-size=3, base-type-encoding=NONE
    OnBdChrgrHndlSts1_2: base-type-size=4, base-type-encoding=NONE
package /EndToEnds
  end to end protection set MainEndToEndSet
    10 x end to end protection:
      HvSysRlySts_BECM1_IEM: end-to-end-profile={category=PROFILE_G, data-ids=21, data-id-mode=0, max-delta-counter-init=1, crc-offset=0, counter-offset=8}, end-to-end-protection-variable-prototype=receiver=IEM.TopLevelComposition.HvSysRlySts.HvSysRlySts
      WhlMotSysTqAllwd_ECM3_IEM: end-to-end-profile={category=PROFILE_G, data-ids=79, data-id-mode=0, max-delta-counter-init=1, crc-offset=0, counter-offset=8}, end-to-end-protection-variable-prototype=receiver=IEM.TopLevelComposition.WhlMotSysTqAllwd.WhlMotSysTqAllwd
      DmcStsRearToEsc_IEM_VDDM: end-to-end-profile={category=PROFILE_G, data-ids=6015, data-id-mode=0, max-delta-counter-init=14, crc-offset=0, counter-offset=8}, end-to-end-protection-variable-prototype=IEM.TopLevelComposition.DmcStsRearToEsc.DmcStsRearToEsc
      WhlMotSysTqEst_IEM_ECM3: end-to-end-profile={category=PROFILE_G, data-ids=69, data-id-mode=0, max-delta-counter-init=13, crc-offset=0, counter-offset=8}, end-to-end-protection-variable-prototype=IEM.TopLevelComposition.WhlMotSysTqEst.WhlMotSysTqEst
      WhlMotSysSpdActSafe_IEM_BBMRoot: end-to-end-profile={category=PROFILE_G, data-ids=7001, data-id-mode=0, max-delta-counter-init=14, crc-offset=0, counter-offset=8}, end-to-end-protection-variable-prototype=IEM.TopLevelComposition.WhlMotSysSpdActSafe.WhlMotSysSpdActSafe
      CrashStsSafe_SRS_IEM: end-to-end-profile={category=PROFILE_G, data-ids=1035, data-id-mode=0, max-delta-counter-init=1, crc-offset=0, counter-offset=8}, end-to-end-protection-variable-prototype=receiver=IEM.TopLevelComposition.CrashStsSafe.CrashStsSafe
      VehMtnSt_VDDM_IEM: end-to-end-profile={category=PROFILE_G, data-ids=54, data-id-mode=0, max-delta-counter-init=1, crc-offset=0, counter-offset=8}, end-to-end-protection-variable-prototype=receiver=IEM.TopLevelComposition.VehMtnSt.VehMtnSt
      VehSpdLgt_VDDM_IEM: end-to-end-profile={category=PROFILE_G, data-ids=55, data-id-mode=0, max-delta-counter-init=14, crc-offset=0, counter-offset=8}, end-to-end-protection-variable-prototype=receiver=IEM.TopLevelComposition.VehSpdLgt.VehSpdLgt
      StcStsToDmc_VDDM_IEM: end-to-end-profile={category=PROFILE_G, data-ids=6565, data-id-mode=0, max-delta-counter-init=14, crc-offset=0, counter-offset=8}, end-to-end-protection-variable-prototype=receiver=IEM.TopLevelComposition.StcStsToDmc.StcStsToDmc
      EscVariantToDmc_VDDM_IEM: end-to-end-profile={category=PROFILE_G, data-ids=6564, data-id-mode=0, max-delta-counter-init=14, crc-offset=0, counter-offset=8}, end-to-end-protection-variable-prototype=receiver=IEM.TopLevelComposition.EscVariantToDmc.EscVariantToDmc
package /ECUExtractIEM/ComponentType
  composition sw component type TopLevelComposition
    13 x port group, all with category=PARTIAL_NETWORKING:
      ParkingDrivingClimatization: inner-group=IEM.ParkingDrivingClimatization
      Diagnostics: inner-group=IEM.Diagnostics
      VehicleDriving: inner-group=IEM.VehicleDriving
      VehicleModeManagement: inner-group=IEM.VehicleModeManagement
      TelematicsConnectivity: inner-group=IEM.TelematicsConnectivity
      HVEnergyStorage: inner-group=IEM.HVEnergyStorage
      Crash: inner-group=IEM.Crash
      InfotainmentPush: inner-group=IEM.InfotainmentPush
      PropulsionStart: inner-group=IEM.PropulsionStart
      GlobalShortDuration: inner-group=IEM.GlobalShortDuration
      Brake: inner-group=IEM.Brake
      ChargingHV: inner-group=IEM.ChargingHV
      Immobilizer: inner-group=IEM.Immobilizer
    component IEM: type=IEM
